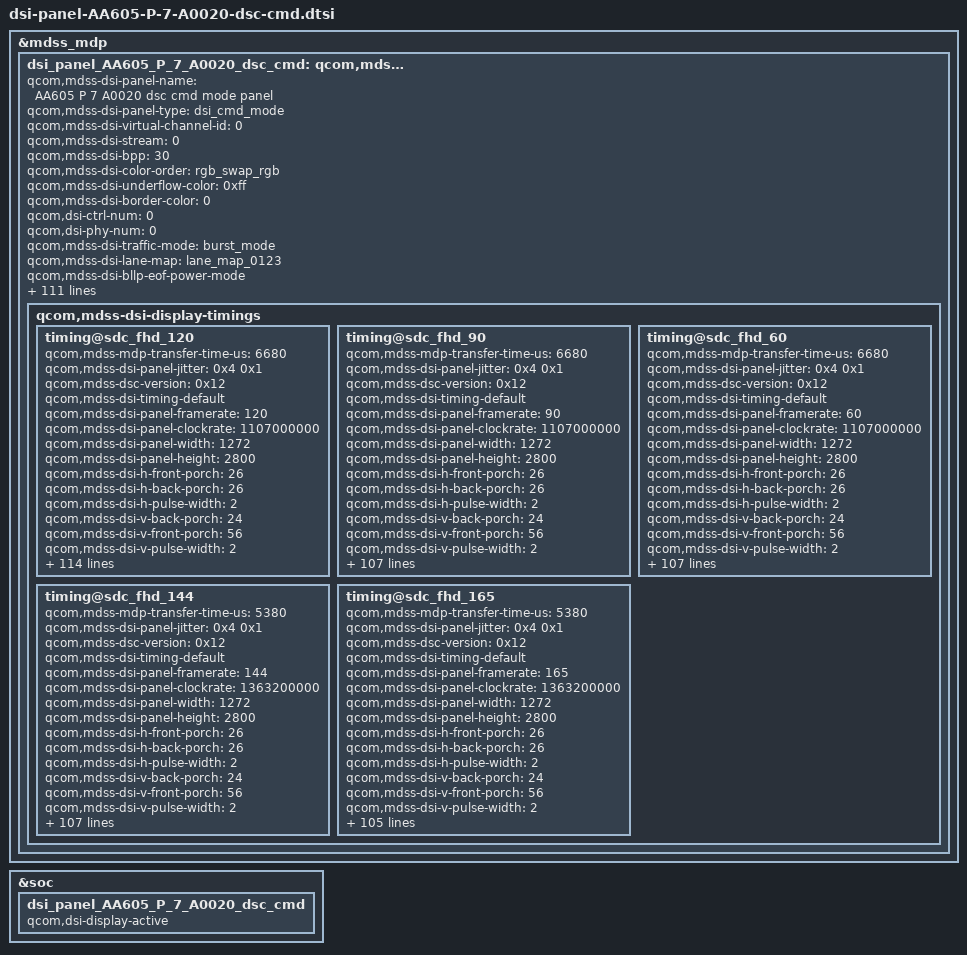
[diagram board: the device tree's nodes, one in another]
&mdss_mdp {
	dsi_panel_AA605_P_7_A0020_dsc_cmd: qcom,mdss_dsi_panel_AA605_P_7_A0020_dsc_cmd {
		qcom,mdss-dsi-panel-name = "AA605 P 7 A0020 dsc cmd mode panel";
		qcom,mdss-dsi-panel-type = "dsi_cmd_mode";
		qcom,mdss-dsi-virtual-channel-id = <0>;
		qcom,mdss-dsi-stream = <0>;
		qcom,mdss-dsi-bpp = <30>;
		qcom,mdss-dsi-color-order = "rgb_swap_rgb";
		qcom,mdss-dsi-underflow-color = <0xff>;
		qcom,mdss-dsi-border-color = <0>;
		qcom,dsi-ctrl-num = <0>;
		qcom,dsi-phy-num = <0>;
		qcom,mdss-dsi-traffic-mode = "burst_mode";
		qcom,mdss-dsi-lane-map = "lane_map_0123";
		qcom,mdss-dsi-bllp-eof-power-mode;
		qcom,mdss-dsi-bllp-power-mode;
		qcom,mdss-dsi-lane-0-state;
		qcom,mdss-dsi-lane-1-state;
		qcom,mdss-dsi-lane-2-state;
		qcom,mdss-dsi-lane-3-state;
		qcom,mdss-dsi-dma-trigger = "trigger_sw";
		qcom,mdss-dsi-dma-schedule-line = <1>;
		qcom,mdss-dsi-dma-schedule-window = <10>;
		qcom,mdss-dsi-mdp-trigger = "none";
		qcom,mdss-dsi-reset-sequence = <1 2>, <0 5>, <1 25>;
		qcom,mdss-dsi-te-pin-select = <1>;
		qcom,mdss-dsi-te-dcs-command = <1>;
		qcom,mdss-pan-physical-width-dimension = <71>;
		qcom,mdss-pan-physical-height-dimension = <157>;
		qcom,mdss-dsi-init-delay-us = <1000>;
		qcom,mdss-dsi-te-check-enable;
		qcom,mdss-dsi-te-using-te-pin;
		//qcom,mdss-dsi-lp11-init;
		qcom,mdss-dsi-wr-mem-start = <0x2c>;
		qcom,mdss-dsi-wr-mem-continue = <0x3c>;
		qcom,mdss-dsi-panel-jitter = <0x4 0x1>;
		qcom,mdss-bl-high2bit;
  		/* HDR Setting */
		qcom,mdss-dsi-panel-hdr-enabled;
		qcom,mdss-dsi-panel-hdr-color-primaries = <15635 16450 34000 16000 13250 34500 7500 3000>;
		//update for [MPC15]android.mediapc.cts.PerformanceClassTest#testDisplayHdr pass
		//qcom,mdss-dsi-panel-peak-brightness = <5400000>;
		qcom,mdss-dsi-panel-peak-brightness = <20000000>;
		qcom,mdss-dsi-panel-average-brightness = <2000000>;
		qcom,mdss-dsi-panel-blackness-level = <4000>;
		qcom,dynamic-mode-switch-enabled;
		qcom,dynamic-mode-switch-type = "dynamic-resolution-switch-immediate";
		qcom,mdss-dsi-display-timings {
			timing@sdc_fhd_120 {
				#include "dsi-panel-AA605-P-7-A0020-common-effect.dtsi"
				#include "dsi-panel-AA605-P-7-A0020-common.dtsi"
				qcom,mdss-mdp-transfer-time-us = <6680>;
				qcom,mdss-dsi-panel-jitter = <0x4 0x1>;
				qcom,mdss-dsc-version = <0x12>;
				qcom,mdss-dsi-timing-default;
				qcom,mdss-dsi-panel-framerate = <120>;
				qcom,mdss-dsi-panel-clockrate = <1107000000>;
				qcom,mdss-dsi-panel-width = <1272>;
				qcom,mdss-dsi-panel-height = <2800>;

				qcom,mdss-dsi-h-front-porch = <26>;
				qcom,mdss-dsi-h-back-porch = <26>;
				qcom,mdss-dsi-h-pulse-width = <2>;
				qcom,mdss-dsi-v-back-porch = <24>;
				qcom,mdss-dsi-v-front-porch = <56>;
				qcom,mdss-dsi-v-pulse-width = <2>;
				qcom,mdss-dsi-h-sync-pulse = <0>;

				oplus,ofp-need-to-sync-data-in-aod-unlocking;
				oplus,ofp-aod-off-insert-black-frame = <1>;
				oplus,ofp-aod-off-black-frame-total-time = <42>;
				oplus,ofp-need-to-separate-backlight;
				oplus,ofp-backlight-on-period = <1>;

				qcom,mdss-dsi-timing-switch-command = [
					39 00 00 40 00 00 04 FF 5A A5 08
					15 00 00 40 00 00 02 98 02
					39 00 00 40 00 00 04 FF 5A A5 4F
					15 00 00 40 00 00 02 80 01
					15 00 00 40 00 00 02 81 06
					15 00 00 40 00 00 02 88 78
					39 00 00 40 00 00 04 FF 5A A5 53
					39 00 00 40 00 00 06 90 44 00 00 04 00
					39 00 00 40 00 00 06 FE 44 00 00 04 00
					39 00 00 40 00 00 06 FE 44 00 00 04 00
					39 00 00 40 00 00 06 FE 44 00 00 04 00
					15 00 00 40 00 00 02 F0 01
					15 00 00 40 00 00 02 00 00
					15 00 00 40 00 00 02 00 00
					15 00 00 40 00 00 02 00 00
					15 00 00 40 00 00 02 00 00
					15 00 00 40 00 00 02 00 00
					15 00 00 40 00 00 02 00 00
					15 00 00 40 00 00 02 00 00
					15 00 00 40 00 00 02 00 00
					39 00 00 40 00 00 04 FF 5A A5 63
					39 00 00 40 00 00 06 F1 20 20 20 20 20
					39 00 00 40 00 00 06 FE 20 20 20 20 20
					39 00 00 40 00 00 06 FE 00 00 00 00 00
					15 00 00 40 00 00 02 FE 00
					15 00 00 40 00 00 02 00 00
					15 00 00 40 00 00 02 00 00
					15 00 00 40 00 00 02 00 00
					15 00 00 40 00 00 02 00 00
					15 00 00 40 00 00 02 00 00
					39 00 00 40 00 00 06 F2 F0 F0 F0 F0 F0
					39 00 00 40 00 00 06 FE F0 F0 F0 F0 F0
					39 00 00 40 00 00 06 FE 00 00 00 00 00
					15 00 00 40 00 00 02 FE 00
					15 00 00 40 00 00 02 00 00
					15 00 00 40 00 00 02 00 00
					15 00 00 40 00 00 02 00 00
					15 00 00 40 00 00 02 00 00
					15 00 00 40 00 00 02 00 00
					39 00 00 40 00 00 06 F3 00 00 00 00 00
					39 00 00 40 00 00 06 FE 00 00 00 00 00
					39 00 00 40 00 00 06 FE 00 00 00 00 00
					15 00 00 40 00 00 02 FE 00
					15 00 00 40 00 00 02 00 00
					15 00 00 40 00 00 02 00 00
					15 00 00 40 00 00 02 00 00
					15 00 00 40 00 00 02 00 00
					15 00 00 40 00 00 02 00 00
					39 00 00 40 00 00 06 F4 00 00 00 00 00
					39 00 00 40 00 00 06 FE 00 00 00 00 00
					39 00 00 40 00 00 06 FE 00 00 00 00 00
					15 00 00 40 00 00 02 FE 00
					15 00 00 40 00 00 02 00 00
					15 00 00 40 00 00 02 00 00
					15 00 00 40 00 00 02 00 00
					15 00 00 40 00 00 02 00 00
					15 00 00 40 00 00 02 00 00
					15 00 00 40 00 00 02 00 00
					15 00 00 40 00 00 02 00 00
					15 00 00 40 00 00 02 00 00
					39 00 00 40 00 00 04 FF 5A A5 53
					15 00 00 40 00 00 02 F0 00
					39 00 00 40 00 00 04 FF 5A A5 00
					39 00 00 40 00 00 04 FF 5A A5 00
					15 00 00 40 00 00 02 60 00
					15 00 00 40 00 00 02 7D 00

					39 00 00 40 00 00 04 FF 5A A5 4F // sync setting
					15 00 00 40 00 00 02 8A 78
					39 00 00 40 00 00 04 FF 5A A5 20 // sync setting
					15 00 00 40 00 00 02 BB 05

					39 00 00 40 00 00 04 FF 5A A5 08
					15 00 00 40 00 00 02 98 A6
					39 00 00 40 00 00 04 FF 5A A5 00
					15 00 00 40 00 00 02 00 00
					39 00 00 40 00 00 04 FF 5A A5 4F
					15 00 00 00 00 00 02 8B 78
				];
				qcom,mdss-dsi-on-command = [
					39 00 00 40 00 00 04 FF 5A A5 08 // 1~2: Sleepoutdon'treload
					15 00 00 40 00 00 02 C8 62
					39 00 00 40 00 00 04 FF 5A A5 21 // 3~4:  Flashreloadenable
					15 00 00 40 00 00 02 A4 38
					39 00 00 40 00 00 04 FF 5A A5 23
					15 00 00 40 00 00 02 85 15
					39 00 00 40 00 00 04 FF 5A A5 06
					15 00 00 40 00 00 02 C6 01
					39 00 00 40 00 00 04 FF 5A A5 08
					15 00 00 40 00 00 02 D2 05
					15 00 00 40 00 00 02 D3 01
					39 00 00 40 00 00 09 ED FC 0C 06 00 E3 F1 09 FF
					39 00 00 00 00 00 09 EE FF FD 82 00 20 03 00 00

					39 00 00 40 00 00 04 FF 5A A5 22
					39 00 00 40 00 00 08 D8 01 03 11 10 3B 18 18 //120&60HZ
					39 00 00 40 00 00 08 D9 01 01 11 10 3B 18 18 //90HZ
					39 00 00 40 00 00 08 DA 00 F8 11 10 2E 17 17 //144HZ
					39 00 00 40 00 00 08 DB 00 F9 11 10 2E 17 17 //165HZ
					39 00 00 40 00 00 0A DC 84 94 BB 00 20 C4 A1 CC 10
					15 00 00 40 00 00 02 DD 01
					15 00 00 40 00 00 02 DE F1
					15 00 00 40 00 00 02 DF 80
					39 00 00 40 00 00 07 E0 02 00 5F 21 00 28

					39 00 00 40 00 00 04 FF 5A A5 02 // sync setting
					39 00 00 40 00 00 03 B0 00 83
					39 00 00 40 00 00 04 FF 5A A5 2D
					15 00 00 40 00 00 02 F6 12
					39 00 00 40 00 00 18 EF 00 00 00 00 00 00 00 00 00 00 00 00 00 00 00 00 00 00 00 00 00 40 0B
					39 00 00 40 00 00 18 F0 00 00 00 00 00 00 00 00 00 00 00 00 00 00 00 00 00 00 00 00 00 40 0B
					39 00 00 40 00 00 04 FF 5A A5 1C // Implementation of measures for addressing abnormal power-on issues of VCI, dvt has already opt
					39 00 00 40 00 00 3A E3 08 00 00 77 01 00 04 14 00 04 14 00 38 10 00 38 10 00 D4 00 00 28 24 00 44 30 00 D4 30 00 47 30 00 F0 00 00 89 00 00 89 00 00 44 00 00 08 00 00 7B 00 00 7B 00 00 24 00 00
					39 00 00 40 00 00 04 FF 5A A5 20 // Correct the reverse configuration of sync settings; dvt has already opt
					15 00 00 40 00 00 02 BA 04 //VSYNC
					15 00 00 00 00 00 02 BB 05 //HSYNC

					39 00 00 40 00 00 04 FF 5A A5 00
					15 00 00 40 00 00 02 7D 00
					15 00 00 40 00 00 02 5E 01
					15 00 00 40 00 00 02 60 00
					15 00 00 40 00 00 02 61 03
					15 00 00 40 00 00 02 6D 01
					15 00 00 40 00 00 02 35 00 // TE on
					15 00 00 40 00 00 02 53 20 // BCOn
					// 120hz
					39 00 00 40 00 00 04 FF 5A A5 53
					39 00 00 40 00 00 06 90 44 00 00 04 00
					39 00 00 40 00 00 06 FE 44 00 00 04 00
					39 00 00 40 00 00 06 FE 44 00 00 04 00
					39 00 00 40 00 00 06 FE 44 00 00 04 00
					15 00 00 40 00 00 02 F0 01
					39 00 00 40 00 00 04 FF 5A A5 63
					39 00 00 40 00 00 06 F1 20 20 20 20 20
					39 00 00 40 00 00 06 FE 20 20 20 20 20
					39 00 00 40 00 00 06 FE 00 00 00 00 00
					15 00 00 40 00 00 02 FE 00
					39 00 00 40 00 00 06 F2 F0 F0 F0 F0 F0
					39 00 00 40 00 00 06 FE F0 F0 F0 F0 F0
					39 00 00 40 00 00 06 FE 00 00 00 00 00
					15 00 00 40 00 00 02 FE 00
					39 00 00 40 00 00 06 F3 00 00 00 00 00
					39 00 00 40 00 00 06 FE 00 00 00 00 00
					39 00 00 40 00 00 06 FE 00 00 00 00 00
					15 00 00 40 00 00 02 FE 00
					39 00 00 40 00 00 06 F4 00 00 00 00 00
					39 00 00 40 00 00 06 FE 00 00 00 00 00
					39 00 00 40 00 00 06 FE 00 00 00 00 00
					15 00 00 40 00 00 02 FE 00
					39 00 00 40 00 00 04 FF 5A A5 53
					15 00 00 40 00 00 02 F0 00
					39 00 00 40 00 00 04 FF 5A A5 00
					39 00 00 40 00 00 04 FF 5A A5 00
					15 00 00 40 00 00 02 60 00
					15 00 00 00 00 00 02 7D 00
					// Evt Output enable for Hsync and Vsync
					39 00 00 40 00 00 04 FF 5A A5 20
					15 00 00 40 00 00 02 BA 04
					15 00 00 00 00 00 02 BB 05
					// ODC ON
					39 00 00 40 00 00 04 FF 5A A5 49
					15 00 00 40 00 00 02 E0 01
					// add demura para
					39 00 00 40 00 00 04 FF 5A A5 53
					15 00 00 40 00 00 02 F0 01
					39 00 00 40 00 00 04 FF 5A A5 63
					39 00 00 40 00 00 11 F1 20 20 20 20 20 20 20 20 20 20 00 00 00 00 00 00
					39 00 00 40 00 00 11 F2 80 80 80 80 80 80 80 80 80 80 00 00 00 00 00 00
					39 00 00 40 00 00 11 F3 00 00 00 00 00 00 00 00 00 00 00 00 00 00 00 00
					39 00 00 40 00 00 11 F4 00 00 00 00 00 00 00 00 00 00 00 00 00 00 00 00
					39 00 00 40 00 00 04 FF 5A A5 53
					15 00 00 00 00 00 02 F0 00

					15 00 00 00 78 00 02 11 00
					15 00 00 00 14 00 02 29 00
				];
				qcom,mdss-dsi-off-command=[
					05 00 00 00 14 00 01 28
					05 00 00 00 78 00 01 10
				];
				qcom,mdss-dsi-timing-switch-compensation-command = [
					39 00 00 40 00 00 04 FF 5A A5 08 // PAGE 08
					15 00 00 40 00 00 02 98 02 //Queue Start Close CDM FIFO Reset
					39 00 00 40 00 00 04 FF 5A A5 4F //CMD_Q
					15 00 00 40 00 00 02 80 01 //Enable MSFC
					15 00 00 40 00 00 02 81 06 //04 Rising,05Falling
					15 00 00 40 00 00 02 88 78 // cmd core0 queue start
					//queue1_str
					39 00 00 40 00 00 04 FF 5A A5 24
					39 00 00 40 00 00 06 C9 00 00 00 10 00
					39 00 00 40 00 00 04 FE 30 00 50
					39 00 00 40 00 00 06 CA 00 70 00 B0 00
					39 00 00 40 00 00 04 FE F0 01 30
					39 00 00 40 00 00 06 CB 01 70 01 C0 02
					39 00 00 40 00 00 04 FE 70 02 F0
					39 00 00 40 00 00 06 CC 03 E0 04 F0 05
					39 00 00 40 00 00 04 FE F0 06 E0
					39 00 00 40 00 00 06 CD 08 F0 0A D0 0B
					39 00 00 40 00 00 04 FE 90 0C C0
					39 00 00 40 00 00 06 CE 0D F0 0E 70 0E
					39 00 00 40 00 00 04 FE F0 0F F0
					39 00 00 40 00 00 04 FF 5A A5 4F // PAGE 4F
					15 00 00 40 00 00 02 8A 78
					//queue2_str
					39 00 00 40 00 00 04 FF 5A A5 00
					15 00 00 40 00 00 02 60 00
					15 00 00 40 00 00 02 7D 00
					39 00 00 40 00 00 04 FF 5A A5 24
					39 00 00 40 00 00 06 C9 00 00 00 10 00
					39 00 00 40 00 00 04 FE 30 00 50
					39 00 00 40 00 00 06 CA 00 70 00 B0 00
					39 00 00 40 00 00 04 FE F0 01 30
					39 00 00 40 00 00 06 CB 01 70 01 F0 02
					39 00 00 40 00 00 04 FE 70 02 F0
					39 00 00 40 00 00 06 CC 03 F0 04 F0 05
					39 00 00 40 00 00 04 FE F0 06 F0
					39 00 00 40 00 00 06 CD 08 F0 0A F0 0B
					39 00 00 40 00 00 04 FE A0 0C F0
					39 00 00 40 00 00 06 CE 0E 10 0E 70 0E
					39 00 00 40 00 00 04 FE F0 0F F0
					//queue2_end
					39 00 00 40 00 00 04 FF 5A A5 53 //Demura Code
					39 00 00 40 00 00 06 90 44 00 00 04 00
					39 00 00 40 00 00 06 FE 44 00 00 04 00
					39 00 00 40 00 00 06 FE 44 00 00 04 00
					39 00 00 40 00 00 06 FE 44 00 00 04 00
					15 00 00 40 00 00 02 F0 01 //MURA_TUNNING
					15 00 00 40 00 00 02 00 00
					15 00 00 40 00 00 02 00 00
					15 00 00 40 00 00 02 00 00
					15 00 00 40 00 00 02 00 00
					15 00 00 40 00 00 02 00 00
					15 00 00 40 00 00 02 00 00
					15 00 00 40 00 00 02 00 00
					15 00 00 40 00 00 02 00 00
					39 00 00 40 00 00 04 FF 5A A5 63
					39 00 00 40 00 00 06 F1 20 20 20 20 20
					39 00 00 40 00 00 06 FE 20 20 20 20 20
					39 00 00 40 00 00 06 FE 00 00 00 00 00
					15 00 00 40 00 00 02 FE 00
					15 00 00 40 00 00 02 00 00
					15 00 00 40 00 00 02 00 00
					15 00 00 40 00 00 02 00 00
					15 00 00 40 00 00 02 00 00
					15 00 00 40 00 00 02 00 00
					39 00 00 40 00 00 06 F2 F0 F0 F0 F0 F0
					39 00 00 40 00 00 06 FE F0 F0 F0 F0 F0
					39 00 00 40 00 00 06 FE 00 00 00 00 00
					15 00 00 40 00 00 02 FE 00
					15 00 00 40 00 00 02 00 00
					15 00 00 40 00 00 02 00 00
					15 00 00 40 00 00 02 00 00
					15 00 00 40 00 00 02 00 00
					15 00 00 40 00 00 02 00 00
					39 00 00 40 00 00 06 F3 00 00 00 00 00
					39 00 00 40 00 00 06 FE 00 00 00 00 00
					39 00 00 40 00 00 06 FE 00 00 00 00 00
					15 00 00 40 00 00 02 FE 00
					15 00 00 40 00 00 02 00 00
					15 00 00 40 00 00 02 00 00
					15 00 00 40 00 00 02 00 00
					15 00 00 40 00 00 02 00 00
					15 00 00 40 00 00 02 00 00
					39 00 00 40 00 00 06 F4 00 00 00 00 00
					39 00 00 40 00 00 06 FE 00 00 00 00 00
					39 00 00 40 00 00 06 FE 00 00 00 00 00
					15 00 00 40 00 00 02 FE 00
					15 00 00 40 00 00 02 00 00
					15 00 00 40 00 00 02 00 00
					15 00 00 40 00 00 02 00 00
					15 00 00 40 00 00 02 00 00
					15 00 00 40 00 00 02 00 00
					15 00 00 40 00 00 02 00 00
					15 00 00 40 00 00 02 00 00
					15 00 00 40 00 00 02 00 00
					39 00 00 40 00 00 04 FF 5A A5 53
					15 00 00 40 00 00 02 F0 00 //
					39 00 00 40 00 00 04 FF 5A A5 4F // sync setting
					15 00 00 40 00 00 02 8A 78
					39 00 00 40 00 00 04 FF 5A A5 20 // sync setting
					15 00 00 40 00 00 02 BB 05
					39 00 00 40 00 00 04 FF 5A A5 00
					39 00 00 40 00 00 04 FF 5A A5 08 //ALL Done open CDM FIFO Reset
					15 00 00 40 00 00 02 98 A6
					39 00 00 40 00 00 04 FF 5A A5 00 //Dummy write
					15 00 00 40 00 00 02 00 00
					39 00 00 40 00 00 04 FF 5A A5 4F // PAGE 4F
					15 00 00 00 00 00 02 8B 78 // cmd core 0 queue all done
					39 00 00 00 00 00 04 FF 5A A5 00
					/* wait for te and blocking one frame */
					39 00 00 20 00 00 04 FF 5A A5 00
				];
				qcom,mdss-dsi-hbm-off-command = [
				];
				qcom,mdss-dsi-hbm-on-command = [
				];
				qcom,mdss-dsi-change-voltage-before-bl-0-command = [
				];
				qcom,mdss-dsi-lhbm-pressed-icon-on-command = [
				];
				qcom,mdss-dsi-lhbm-pressed-icon-off-command = [
				];
				qcom,mdss-dsi-lp1-command = [
					39 00 00 40 00 00 04 FF 5A A5 08
					15 00 00 40 00 00 02 98 02
					39 00 00 40 00 00 04 FF 5A A5 4F
					15 00 00 40 00 00 02 80 01
					15 00 00 40 00 00 02 81 06
					15 00 00 40 00 00 02 88 78
					39 00 00 40 00 00 04 FF 5A A5 02
					39 00 00 40 00 00 03 84 01 1E
					39 00 00 40 00 00 04 FF 5A A5 00
					15 00 00 40 00 00 02 39 00
					39 00 00 40 00 00 04 FF 5A A5 08
					15 00 00 40 00 00 02 98 A6
					39 00 00 40 00 00 04 FF 5A A5 00
					15 00 00 40 00 00 02 00 00
					39 00 00 40 00 00 04 FF 5A A5 4F
					15 00 00 00 00 00 02 8B 78
					39 00 00 00 00 00 05 51 00 00 03 DA
				];
				qcom,mdss-dsi-nolp-command = [
					39 00 00 40 00 00 04 FF 5A A5 08
					15 00 00 40 00 00 02 98 02
					39 00 00 40 00 00 04 FF 5A A5 4F
					15 00 00 40 00 00 02 80 01
					15 00 00 40 00 00 02 81 06
					15 00 00 40 00 00 02 88 78
					39 00 00 40 00 00 04 FF 5A A5 02
					39 00 00 40 00 00 03 84 01 05
					39 00 00 40 00 00 04 FF 5A A5 00
					15 00 00 40 00 00 02 38 00
					39 00 00 40 00 00 04 FF 5A A5 08
					15 00 00 40 00 00 02 98 A6
					39 00 00 40 00 00 04 FF 5A A5 00
					15 00 00 40 00 00 02 00 00
					39 00 00 40 00 00 04 FF 5A A5 4F
					15 00 00 00 00 00 02 8B 78
				];
				qcom,mdss-dsi-aod-off-pwm-mode2-command = [
				];
				qcom,mdss-dsi-aod-off-compensation-command = [
				];
				qcom,mdss-dsi-aod-off-compensation-onepulse-command = [
				];
				qcom,mdss-dsi-aod-high-mode-command = [
					39 00 00 40 00 00 04 FF 5A A5 00
					39 00 00 00 00 00 05 51 00 00 03 DA
				];
				qcom,mdss-dsi-aod-low-mode-command = [
					39 00 00 40 00 00 04 FF 5A A5 00
					39 00 00 00 00 00 05 51 00 00 01 B9
				];
				qcom,mdss-dsi-ultra-low-power-aod-on-command = [
				];
				qcom,mdss-dsi-ultra-low-power-aod-off-command = [
				];
				/* pwm */
				qcom,mdss-dsi-pwm-state-l3tol2-command = [
				];
				qcom,mdss-dsi-pwm-state-l2tol3-command = [
				];
				qcom,mdss-dsi-pwm-switch-mode0-command= [
				];
				qcom,mdss-dsi-pwm-switch-mode2-command = [
				];
				qcom,mdss-dsi-timming-switch-pwm-mode2-command = [
				];
				qcom,mdss-dsi-pwm-switch-mode2-panel-on-command = [
				];
				qcom,mdss-dsi-pwm-state-l1tol3-command = [
				];
				qcom,mdss-dsi-pwm-state-l3tol1-command = [
				];
				qcom,mdss-dsi-hbm-max-command = [
				];
				qcom,mdss-dsi-hbm-exit-max-command = [
				];
				qcom,mdss-dsi-lp1-command-state = "dsi_lp_sync1_mode";
				qcom,mdss-dsi-nolp-command-state = "dsi_lp_sync1_mode";
				qcom,mdss-dsi-aod-off-pwm-mode2-command-state = "dsi_hs_sync1_mode";
				qcom,mdss-dsi-aod-off-compensation-command-state = "dsi_lp_sync1_mode";
				qcom,mdss-dsi-aod-off-compensation-onepulse-command-state = "dsi_lp_sync1_mode";
				qcom,mdss-dsi-nolp-hpwm-command-state = "dsi_lp_sync1_mode";
				qcom,mdss-dsi-hbm-on-command-state = "dsi_hs_sync1_mode";
				qcom,mdss-dsi-hbm-off-command-state = "dsi_hs_sync1_mode";
				qcom,mdss-dsi-panel-read-register-open-state = "dsi_lp_mode";
				qcom,mdss-dsi-panel-read-register-close-state = "dsi_lp_mode";
				qcom,mdss-dsi-lhbm-pressed-icon-gamma-command-state = "dsi_lp_mode";
				qcom,mdss-dsi-lhbm-pressed-icon-grayscale-command-state = "dsi_lp_mode";
				qcom,mdss-dsi-lhbm-pressed-icon-on-command-state = "dsi_lp_mode";
				qcom,mdss-dsi-lhbm-pressed-icon-off-command-state = "dsi_lp_mode";
				qcom,mdss-dsi-lhbm-dbv-alpha-command-state = "dsi_hs_mode";

				qcom,mdss-dsi-reset-scanline-command-state = "dsi_hs_mode";
				qcom,mdss-dsi-recovery-scanline-command-state = "dsi_hs_mode";

				qcom,mdss-dsi-osc-track-on-command-state = "dsi_hs_mode";
				qcom,mdss-dsi-osc-track-off-command-state = "dsi_hs_mode";
				qcom,mdss-dsi-hbm-max-command-state = "dsi_hs_mode";
				qcom,mdss-dsi-hbm-exit-max-command-state = "dsi_hs_mode";

				qcom,lm-split = <636 636>;
				qcom,compression-mode = "dsc";
				qcom,mdss-dsc-encoders = <2>;
				qcom,mdss-dsc-slice-height = <20>;
				qcom,mdss-dsc-slice-width = <636>;
				qcom,mdss-dsc-slice-per-pkt = <2>;
				qcom,mdss-dsc-bit-per-component = <10>;
				qcom,mdss-dsc-bit-per-pixel = <8>;
				qcom,mdss-dsc-block-prediction-enable;
			};
			timing@sdc_fhd_90 {
				#include "dsi-panel-AA605-P-7-A0020-common-effect.dtsi"
				#include "dsi-panel-AA605-P-7-A0020-common.dtsi"
				qcom,mdss-mdp-transfer-time-us = <6680>;
				qcom,mdss-dsi-panel-jitter = <0x4 0x1>;
				qcom,mdss-dsc-version = <0x12>;
				qcom,mdss-dsi-timing-default;
				qcom,mdss-dsi-panel-framerate = <90>;
				qcom,mdss-dsi-panel-clockrate = <1107000000>;
				qcom,mdss-dsi-panel-width = <1272>;
				qcom,mdss-dsi-panel-height = <2800>;

				qcom,mdss-dsi-h-front-porch = <26>;
				qcom,mdss-dsi-h-back-porch = <26>;
				qcom,mdss-dsi-h-pulse-width = <2>;
				qcom,mdss-dsi-v-back-porch = <24>;
				qcom,mdss-dsi-v-front-porch = <56>;
				qcom,mdss-dsi-v-pulse-width = <2>;
				qcom,mdss-dsi-h-sync-pulse = <0>;

				oplus,ofp-need-to-sync-data-in-aod-unlocking;
				oplus,ofp-aod-off-insert-black-frame = <1>;
				oplus,ofp-aod-off-black-frame-total-time = <42>;
				oplus,ofp-need-to-separate-backlight;
				oplus,ofp-backlight-on-period = <1>;

				qcom,mdss-dsi-timing-switch-command = [
					39 00 00 40 00 00 04 FF 5A A5 08
					15 00 00 40 00 00 02 98 02
					39 00 00 40 00 00 04 FF 5A A5 4F
					15 00 00 40 00 00 02 80 01
					15 00 00 40 00 00 02 81 06
					15 00 00 40 00 00 02 88 78
					39 00 00 40 00 00 04 FF 5A A5 53 //Demura Code
					39 00 00 40 00 00 06 90 44 00 00 03 D0
					39 00 00 40 00 00 06 FE 44 00 00 04 00
					39 00 00 40 00 00 06 FE 44 00 00 04 00
					39 00 00 40 00 00 06 FE 44 00 00 04 00
					15 00 00 40 00 00 02 F0 01
					15 00 00 40 00 00 02 00 00
					15 00 00 40 00 00 02 00 00
					15 00 00 40 00 00 02 00 00
					15 00 00 40 00 00 02 00 00
					15 00 00 40 00 00 02 00 00
					15 00 00 40 00 00 02 00 00
					15 00 00 40 00 00 02 00 00
					15 00 00 40 00 00 02 00 00
					39 00 00 40 00 00 04 FF 5A A5 63
					39 00 00 40 00 00 06 F1 20 20 20 20 20
					39 00 00 40 00 00 06 FE 20 20 20 20 20
					39 00 00 40 00 00 06 FE 00 00 00 00 00
					15 00 00 40 00 00 02 FE 00
					15 00 00 40 00 00 02 00 00
					15 00 00 40 00 00 02 00 00
					15 00 00 40 00 00 02 00 00
					15 00 00 40 00 00 02 00 00
					15 00 00 40 00 00 02 00 00
					39 00 00 40 00 00 06 F2 F0 F0 F0 F0 F0
					39 00 00 40 00 00 06 FE F0 F0 F0 F0 F0
					39 00 00 40 00 00 06 FE 00 00 00 00 00
					15 00 00 40 00 00 02 FE 00
					15 00 00 40 00 00 02 00 00
					15 00 00 40 00 00 02 00 00
					15 00 00 40 00 00 02 00 00
					15 00 00 40 00 00 02 00 00
					15 00 00 40 00 00 02 00 00
					39 00 00 40 00 00 06 F3 00 00 00 00 00
					39 00 00 40 00 00 06 FE 00 00 00 00 00
					39 00 00 40 00 00 06 FE 00 00 00 00 00
					15 00 00 40 00 00 02 FE 00
					15 00 00 40 00 00 02 00 00
					15 00 00 40 00 00 02 00 00
					15 00 00 40 00 00 02 00 00
					15 00 00 40 00 00 02 00 00
					15 00 00 40 00 00 02 00 00
					39 00 00 40 00 00 06 F4 00 00 00 00 00
					39 00 00 40 00 00 06 FE 00 00 00 00 00
					39 00 00 40 00 00 06 FE 00 00 00 00 00
					15 00 00 40 00 00 02 FE 00
					15 00 00 40 00 00 02 00 00
					15 00 00 40 00 00 02 00 00
					15 00 00 40 00 00 02 00 00
					15 00 00 40 00 00 02 00 00
					15 00 00 40 00 00 02 00 00
					15 00 00 40 00 00 02 00 00
					15 00 00 40 00 00 02 00 00
					15 00 00 40 00 00 02 00 00
					39 00 00 40 00 00 04 FF 5A A5 53
					15 00 00 40 00 00 02 F0 00
					39 00 00 40 00 00 04 FF 5A A5 00
					39 00 00 40 00 00 04 FF 5A A5 00
					15 00 00 40 00 00 02 60 04
					15 00 00 40 00 00 02 7D 01
					39 00 00 40 00 00 04 FF 5A A5 4F // sync setting
					15 00 00 40 00 00 02 8A 78
					39 00 00 40 00 00 04 FF 5A A5 20 // sync setting
					15 00 00 40 00 00 02 BB 00
					39 00 00 40 00 00 04 FF 5A A5 08
					15 00 00 40 00 00 02 98 A6
					39 00 00 40 00 00 04 FF 5A A5 00
					15 00 00 40 00 00 02 00 00
					39 00 00 40 00 00 04 FF 5A A5 4F
					15 00 00 00 00 00 02 8B 78
				];
				qcom,mdss-dsi-on-command = [
					39 00 00 40 00 00 04 FF 5A A5 08 // 1~2: Sleepoutdon'treload
					15 00 00 40 00 00 02 C8 62
					39 00 00 40 00 00 04 FF 5A A5 21 // 3~4:  Flashreloadenable
					15 00 00 40 00 00 02 A4 38
					39 00 00 40 00 00 04 FF 5A A5 23
					15 00 00 40 00 00 02 85 15
					39 00 00 40 00 00 04 FF 5A A5 06
					15 00 00 40 00 00 02 C6 01
					39 00 00 40 00 00 04 FF 5A A5 08
					15 00 00 40 00 00 02 D2 05
					15 00 00 40 00 00 02 D3 01
					39 00 00 40 00 00 09 ED FC 0C 06 00 E3 F1 09 FF
					39 00 00 00 00 00 09 EE FF FD 82 00 20 03 00 00

					39 00 00 40 00 00 04 FF 5A A5 22
					39 00 00 40 00 00 08 D8 01 03 11 10 3B 18 18 //120&60HZ
					39 00 00 40 00 00 08 D9 01 01 11 10 3B 18 18 //90HZ
					39 00 00 40 00 00 08 DA 00 F8 11 10 2E 17 17 //144HZ
					39 00 00 40 00 00 08 DB 00 F9 11 10 2E 17 17 //165HZ
					39 00 00 40 00 00 0A DC 84 94 BB 00 20 C4 A1 CC 10
					15 00 00 40 00 00 02 DD 01
					15 00 00 40 00 00 02 DE F1
					15 00 00 40 00 00 02 DF 80
					39 00 00 40 00 00 07 E0 02 00 5F 21 00 28

					39 00 00 40 00 00 04 FF 5A A5 02 // sync setting
					39 00 00 40 00 00 03 B0 00 83
					39 00 00 40 00 00 04 FF 5A A5 2D
					15 00 00 40 00 00 02 F6 12
					39 00 00 40 00 00 18 EF 00 00 00 00 00 00 00 00 00 00 00 00 00 00 00 00 00 00 00 00 00 40 0B
					39 00 00 40 00 00 18 F0 00 00 00 00 00 00 00 00 00 00 00 00 00 00 00 00 00 00 00 00 00 40 0B
					39 00 00 40 00 00 04 FF 5A A5 1C // Implementation of measures for addressing abnormal power-on issues of VCI, dvt has already opt
					39 00 00 40 00 00 3A E3 08 00 00 77 01 00 04 14 00 04 14 00 38 10 00 38 10 00 D4 00 00 28 24 00 44 30 00 D4 30 00 47 30 00 F0 00 00 89 00 00 89 00 00 44 00 00 08 00 00 7B 00 00 7B 00 00 24 00 00
					39 00 00 40 00 00 04 FF 5A A5 20 // Correct the reverse configuration of sync settings; dvt has already opt
					15 00 00 40 00 00 02 BA 04 //VSYNC
					15 00 00 00 00 00 02 BB 05 //HSYNC

					39 00 00 40 00 00 04 FF 5A A5 00
					15 00 00 40 00 00 02 7D 00
					15 00 00 40 00 00 02 5E 01
					15 00 00 40 00 00 02 60 00
					15 00 00 40 00 00 02 61 03
					15 00 00 40 00 00 02 6D 01
					15 00 00 40 00 00 02 35 00 // TE on
					15 00 00 40 00 00 02 53 20 // BCOn
					// 90hz
					39 00 00 40 00 00 04 FF 5A A5 53
					39 00 00 40 00 00 06 90 44 00 00 03 D0
					39 00 00 40 00 00 06 FE 44 00 00 04 00
					39 00 00 40 00 00 06 FE 44 00 00 04 00
					39 00 00 40 00 00 06 FE 44 00 00 04 00
					15 00 00 40 00 00 02 F0 01
					39 00 00 40 00 00 04 FF 5A A5 63
					39 00 00 40 00 00 06 F1 20 20 20 20 20
					39 00 00 40 00 00 06 FE 20 20 20 20 20
					39 00 00 40 00 00 06 FE 00 00 00 00 00
					15 00 00 40 00 00 02 FE 00
					39 00 00 40 00 00 06 F2 F0 F0 F0 F0 F0
					39 00 00 40 00 00 06 FE F0 F0 F0 F0 F0
					39 00 00 40 00 00 06 FE 00 00 00 00 00
					15 00 00 40 00 00 02 FE 00
					39 00 00 40 00 00 06 F3 00 00 00 00 00
					39 00 00 40 00 00 06 FE 00 00 00 00 00
					39 00 00 40 00 00 06 FE 00 00 00 00 00
					15 00 00 40 00 00 02 FE 00
					39 00 00 40 00 00 06 F4 00 00 00 00 00
					39 00 00 40 00 00 06 FE 00 00 00 00 00
					39 00 00 40 00 00 06 FE 00 00 00 00 00
					15 00 00 40 00 00 02 FE 00
					39 00 00 40 00 00 04 FF 5A A5 53
					15 00 00 40 00 00 02 F0 00
					39 00 00 40 00 00 04 FF 5A A5 00
					39 00 00 40 00 00 04 FF 5A A5 00
					15 00 00 40 00 00 02 60 04
					15 00 00 00 00 00 02 7D 01
					// Evt Output enable for Hsync and Vsync
					39 00 00 40 00 00 04 FF 5A A5 20
					15 00 00 40 00 00 02 BA 04
					15 00 00 00 00 00 02 BB 05
					// ODC ON
					39 00 00 40 00 00 04 FF 5A A5 49
					15 00 00 40 00 00 02 E0 01
					// add demura para
					39 00 00 40 00 00 04 FF 5A A5 53
					15 00 00 40 00 00 02 F0 01
					39 00 00 40 00 00 04 FF 5A A5 63
					39 00 00 40 00 00 11 F1 20 20 20 20 20 20 20 20 20 20 00 00 00 00 00 00
					39 00 00 40 00 00 11 F2 80 80 80 80 80 80 80 80 80 80 00 00 00 00 00 00
					39 00 00 40 00 00 11 F3 00 00 00 00 00 00 00 00 00 00 00 00 00 00 00 00
					39 00 00 40 00 00 11 F4 00 00 00 00 00 00 00 00 00 00 00 00 00 00 00 00
					39 00 00 40 00 00 04 FF 5A A5 53
					15 00 00 00 00 00 02 F0 00

					15 00 00 00 78 00 02 11 00
					15 00 00 00 14 00 02 29 00
				];
				qcom,mdss-dsi-off-command=[
					05 00 00 00 14 00 01 28
					05 00 00 00 78 00 01 10
				];
				qcom,mdss-dsi-timing-switch-compensation-command = [
					39 00 00 40 00 00 04 FF 5A A5 08 // PAGE 08
					15 00 00 40 00 00 02 98 02 //Queue Start Close CDM FIFO Reset
					39 00 00 40 00 00 04 FF 5A A5 4F //CMD_Q
					15 00 00 40 00 00 02 80 01 //Enable MSFC
					15 00 00 40 00 00 02 81 06 //04 Rising,05Falling
					15 00 00 40 00 00 02 88 78 // cmd core0 queue start
					//queue1_str
					39 00 00 40 00 00 04 FF 5A A5 24
					39 00 00 40 00 00 06 C9 00 00 00 10 00
					39 00 00 40 00 00 04 FE 30 00 50
					39 00 00 40 00 00 06 CA 00 70 00 B0 00
					39 00 00 40 00 00 04 FE F0 01 30
					39 00 00 40 00 00 06 CB 01 70 01 C0 02
					39 00 00 40 00 00 04 FE 70 02 F0
					39 00 00 40 00 00 06 CC 03 E0 04 F0 05
					39 00 00 40 00 00 04 FE F0 06 E0
					39 00 00 40 00 00 06 CD 08 F0 0A D0 0B
					39 00 00 40 00 00 04 FE 90 0C C0
					39 00 00 40 00 00 06 CE 0D F0 0E 70 0E
					39 00 00 40 00 00 04 FE F0 0F F0
					39 00 00 40 00 00 04 FF 5A A5 4F // PAGE 4F
					15 00 00 40 00 00 02 8A 78
					//queue2_str
					39 00 00 40 00 00 04 FF 5A A5 00
					15 00 00 40 00 00 02 60 04
					15 00 00 40 00 00 02 7D 01
					39 00 00 40 00 00 04 FF 5A A5 24
					39 00 00 40 00 00 06 C9 00 00 00 10 00
					39 00 00 40 00 00 04 FE 30 00 50
					39 00 00 40 00 00 06 CA 00 70 00 B0 00
					39 00 00 40 00 00 04 FE F0 01 30
					39 00 00 40 00 00 06 CB 01 70 01 F0 02
					39 00 00 40 00 00 04 FE 70 02 F0
					39 00 00 40 00 00 06 CC 03 F0 04 F0 05
					39 00 00 40 00 00 04 FE F0 06 F0
					39 00 00 40 00 00 06 CD 08 F0 0A F0 0B
					39 00 00 40 00 00 04 FE A0 0C F0
					39 00 00 40 00 00 06 CE 0E 10 0E 70 0E
					39 00 00 40 00 00 04 FE F0 0F F0
					//queue2_end
					39 00 00 40 00 00 04 FF 5A A5 53 //Demura Code
					39 00 00 40 00 00 06 90 44 00 00 03 D0
					39 00 00 40 00 00 06 FE 44 00 00 04 00
					39 00 00 40 00 00 06 FE 44 00 00 04 00
					39 00 00 40 00 00 06 FE 44 00 00 04 00
					15 00 00 40 00 00 02 F0 01 //MURA_TUNNING
					15 00 00 40 00 00 02 00 00
					15 00 00 40 00 00 02 00 00
					15 00 00 40 00 00 02 00 00
					15 00 00 40 00 00 02 00 00
					15 00 00 40 00 00 02 00 00
					15 00 00 40 00 00 02 00 00
					15 00 00 40 00 00 02 00 00
					15 00 00 40 00 00 02 00 00
					39 00 00 40 00 00 04 FF 5A A5 63
					39 00 00 40 00 00 06 F1 20 20 20 20 20
					39 00 00 40 00 00 06 FE 20 20 20 20 20
					39 00 00 40 00 00 06 FE 00 00 00 00 00
					15 00 00 40 00 00 02 FE 00
					15 00 00 40 00 00 02 00 00
					15 00 00 40 00 00 02 00 00
					15 00 00 40 00 00 02 00 00
					15 00 00 40 00 00 02 00 00
					15 00 00 40 00 00 02 00 00
					39 00 00 40 00 00 06 F2 F0 F0 F0 F0 F0
					39 00 00 40 00 00 06 FE F0 F0 F0 F0 F0
					39 00 00 40 00 00 06 FE 00 00 00 00 00
					15 00 00 40 00 00 02 FE 00
					15 00 00 40 00 00 02 00 00
					15 00 00 40 00 00 02 00 00
					15 00 00 40 00 00 02 00 00
					15 00 00 40 00 00 02 00 00
					15 00 00 40 00 00 02 00 00
					39 00 00 40 00 00 06 F3 00 00 00 00 00
					39 00 00 40 00 00 06 FE 00 00 00 00 00
					39 00 00 40 00 00 06 FE 00 00 00 00 00
					15 00 00 40 00 00 02 FE 00
					15 00 00 40 00 00 02 00 00
					15 00 00 40 00 00 02 00 00
					15 00 00 40 00 00 02 00 00
					15 00 00 40 00 00 02 00 00
					15 00 00 40 00 00 02 00 00
					39 00 00 40 00 00 06 F4 00 00 00 00 00
					39 00 00 40 00 00 06 FE 00 00 00 00 00
					39 00 00 40 00 00 06 FE 00 00 00 00 00
					15 00 00 40 00 00 02 FE 00
					15 00 00 40 00 00 02 00 00
					15 00 00 40 00 00 02 00 00
					15 00 00 40 00 00 02 00 00
					15 00 00 40 00 00 02 00 00
					15 00 00 40 00 00 02 00 00
					15 00 00 40 00 00 02 00 00
					15 00 00 40 00 00 02 00 00
					15 00 00 40 00 00 02 00 00
					39 00 00 40 00 00 04 FF 5A A5 53
					15 00 00 40 00 00 02 F0 00 //
					39 00 00 40 00 00 04 FF 5A A5 4F // sync setting
					15 00 00 40 00 00 02 8A 78
					39 00 00 40 00 00 04 FF 5A A5 20 // sync setting
					15 00 00 40 00 00 02 BB 00
					39 00 00 40 00 00 04 FF 5A A5 00
					39 00 00 40 00 00 04 FF 5A A5 08 //ALL Done open CDM FIFO Reset
					15 00 00 40 00 00 02 98 A6
					39 00 00 40 00 00 04 FF 5A A5 00 //Dummy write
					15 00 00 40 00 00 02 00 00
					39 00 00 40 00 00 04 FF 5A A5 4F // PAGE 4F
					15 00 00 00 00 00 02 8B 78 // cmd core 0 queue all done
					39 00 00 00 00 00 04 FF 5A A5 00
					/* wait for te and blocking one frame */
					39 00 00 20 00 00 04 FF 5A A5 00
				];
				qcom,mdss-dsi-hbm-off-command = [
				];
				qcom,mdss-dsi-hbm-on-command = [
				];
				qcom,mdss-dsi-change-voltage-before-bl-0-command = [
				];
				qcom,mdss-dsi-lhbm-pressed-icon-on-command = [
				];
				qcom,mdss-dsi-lhbm-pressed-icon-off-command = [
				];
				qcom,mdss-dsi-lp1-command = [
					39 00 00 40 00 00 04 FF 5A A5 08
					15 00 00 40 00 00 02 98 02
					39 00 00 40 00 00 04 FF 5A A5 4F
					15 00 00 40 00 00 02 80 01
					15 00 00 40 00 00 02 81 06
					15 00 00 40 00 00 02 88 78
					39 00 00 40 00 00 04 FF 5A A5 02
					39 00 00 40 00 00 03 84 01 1E
					39 00 00 40 00 00 04 FF 5A A5 00
					15 00 00 40 00 00 02 39 00
					39 00 00 40 00 00 04 FF 5A A5 08
					15 00 00 40 00 00 02 98 A6
					39 00 00 40 00 00 04 FF 5A A5 00
					15 00 00 40 00 00 02 00 00
					39 00 00 40 00 00 04 FF 5A A5 4F
					15 00 00 00 00 00 02 8B 78
					39 00 00 00 00 00 05 51 00 00 03 DA
				];
				qcom,mdss-dsi-nolp-command = [
					39 00 00 40 00 00 04 FF 5A A5 08
					15 00 00 40 00 00 02 98 02
					39 00 00 40 00 00 04 FF 5A A5 4F
					15 00 00 40 00 00 02 80 01
					15 00 00 40 00 00 02 81 06
					15 00 00 40 00 00 02 88 78
					39 00 00 40 00 00 04 FF 5A A5 02
					39 00 00 40 00 00 03 84 01 05
					39 00 00 40 00 00 04 FF 5A A5 00
					15 00 00 40 00 00 02 38 00
					39 00 00 40 00 00 04 FF 5A A5 08
					15 00 00 40 00 00 02 98 A6
					39 00 00 40 00 00 04 FF 5A A5 00
					15 00 00 40 00 00 02 00 00
					39 00 00 40 00 00 04 FF 5A A5 4F
					15 00 00 00 00 00 02 8B 78
				];
				qcom,mdss-dsi-aod-off-pwm-mode2-command = [
				];
				qcom,mdss-dsi-aod-off-compensation-command = [
				];
				qcom,mdss-dsi-aod-off-compensation-onepulse-command = [
				];
				qcom,mdss-dsi-aod-high-mode-command = [
					39 00 00 40 00 00 04 FF 5A A5 00
					39 00 00 00 00 00 05 51 00 00 03 DA
				];
				qcom,mdss-dsi-aod-low-mode-command = [
					39 00 00 40 00 00 04 FF 5A A5 00
					39 00 00 00 00 00 05 51 00 00 01 B9
				];
				qcom,mdss-dsi-ultra-low-power-aod-on-command = [
				];
				qcom,mdss-dsi-ultra-low-power-aod-off-command = [
				];
				/* pwm */
				qcom,mdss-dsi-pwm-state-l3tol2-command = [
				];
				qcom,mdss-dsi-pwm-state-l2tol3-command = [
				];
				qcom,mdss-dsi-pwm-switch-mode0-command= [
				];
				qcom,mdss-dsi-pwm-switch-mode2-command = [
				];
				qcom,mdss-dsi-timming-switch-pwm-mode2-command = [
				];
				qcom,mdss-dsi-pwm-switch-mode2-panel-on-command = [
				];
				qcom,mdss-dsi-pwm-state-l1tol3-command = [
				];
				qcom,mdss-dsi-pwm-state-l3tol1-command = [
				];
				qcom,mdss-dsi-hbm-max-command = [
				];
				qcom,mdss-dsi-hbm-exit-max-command = [
				];
				qcom,mdss-dsi-lp1-command-state = "dsi_lp_sync1_mode";
				qcom,mdss-dsi-nolp-command-state = "dsi_lp_sync1_mode";
				qcom,mdss-dsi-aod-off-pwm-mode2-command-state = "dsi_hs_sync1_mode";
				qcom,mdss-dsi-aod-off-compensation-command-state = "dsi_lp_sync1_mode";
				qcom,mdss-dsi-aod-off-compensation-onepulse-command-state = "dsi_lp_sync1_mode";
				qcom,mdss-dsi-nolp-hpwm-command-state = "dsi_lp_sync1_mode";
				qcom,mdss-dsi-hbm-on-command-state = "dsi_hs_sync1_mode";
				qcom,mdss-dsi-hbm-off-command-state = "dsi_hs_sync1_mode";
				qcom,mdss-dsi-panel-read-register-open-state = "dsi_lp_mode";
				qcom,mdss-dsi-panel-read-register-close-state = "dsi_lp_mode";
				qcom,mdss-dsi-lhbm-pressed-icon-gamma-command-state = "dsi_lp_mode";
				qcom,mdss-dsi-lhbm-pressed-icon-grayscale-command-state = "dsi_lp_mode";
				qcom,mdss-dsi-lhbm-pressed-icon-on-command-state = "dsi_lp_mode";
				qcom,mdss-dsi-lhbm-pressed-icon-off-command-state = "dsi_lp_mode";
				qcom,mdss-dsi-lhbm-dbv-alpha-command-state = "dsi_hs_mode";

				qcom,mdss-dsi-reset-scanline-command-state = "dsi_hs_mode";
				qcom,mdss-dsi-recovery-scanline-command-state = "dsi_hs_mode";

				qcom,mdss-dsi-osc-track-on-command-state = "dsi_hs_mode";
				qcom,mdss-dsi-osc-track-off-command-state = "dsi_hs_mode";
				qcom,mdss-dsi-hbm-max-command-state = "dsi_hs_mode";
				qcom,mdss-dsi-hbm-exit-max-command-state = "dsi_hs_mode";

				qcom,lm-split = <636 636>;
				qcom,compression-mode = "dsc";
				qcom,mdss-dsc-encoders = <2>;
				qcom,mdss-dsc-slice-height = <20>;
				qcom,mdss-dsc-slice-width = <636>;
				qcom,mdss-dsc-slice-per-pkt = <2>;
				qcom,mdss-dsc-bit-per-component = <10>;
				qcom,mdss-dsc-bit-per-pixel = <8>;
				qcom,mdss-dsc-block-prediction-enable;
			};
			timing@sdc_fhd_60 {
				#include "dsi-panel-AA605-P-7-A0020-common-effect.dtsi"
				#include "dsi-panel-AA605-P-7-A0020-common.dtsi"
				qcom,mdss-mdp-transfer-time-us = <6680>;
				qcom,mdss-dsi-panel-jitter = <0x4 0x1>;
				qcom,mdss-dsc-version = <0x12>;
				qcom,mdss-dsi-timing-default;
				qcom,mdss-dsi-panel-framerate = <60>;
				qcom,mdss-dsi-panel-clockrate = <1107000000>;
				qcom,mdss-dsi-panel-width = <1272>;
				qcom,mdss-dsi-panel-height = <2800>;

				qcom,mdss-dsi-h-front-porch = <26>;
				qcom,mdss-dsi-h-back-porch = <26>;
				qcom,mdss-dsi-h-pulse-width = <2>;
				qcom,mdss-dsi-v-back-porch = <24>;
				qcom,mdss-dsi-v-front-porch = <56>;
				qcom,mdss-dsi-v-pulse-width = <2>;
				qcom,mdss-dsi-h-sync-pulse = <0>;

				oplus,ofp-need-to-sync-data-in-aod-unlocking;
				oplus,ofp-aod-off-insert-black-frame = <1>;
				oplus,ofp-aod-off-black-frame-total-time = <42>;
				oplus,ofp-need-to-separate-backlight;
				oplus,ofp-backlight-on-period = <1>;

				qcom,mdss-dsi-timing-switch-command = [
					39 00 00 40 00 00 04 FF 5A A5 08
					15 00 00 40 00 00 02 98 02
					39 00 00 40 00 00 04 FF 5A A5 4F
					15 00 00 40 00 00 02 80 01
					15 00 00 40 00 00 02 81 06
					15 00 00 40 00 00 02 88 78
					39 00 00 40 00 00 04 FF 5A A5 53 //Demura Code
					39 00 00 40 00 00 06 90 44 00 00 03 10
					39 00 00 40 00 00 06 FE 44 00 00 04 00
					39 00 00 40 00 00 06 FE 44 00 00 04 00
					39 00 00 40 00 00 06 FE 44 00 00 04 00
					15 00 00 40 00 00 02 F0 01
					15 00 00 40 00 00 02 00 00
					15 00 00 40 00 00 02 00 00
					15 00 00 40 00 00 02 00 00
					15 00 00 40 00 00 02 00 00
					15 00 00 40 00 00 02 00 00
					15 00 00 40 00 00 02 00 00
					15 00 00 40 00 00 02 00 00
					15 00 00 40 00 00 02 00 00
					39 00 00 40 00 00 04 FF 5A A5 63
					39 00 00 40 00 00 06 F1 20 20 20 20 20
					39 00 00 40 00 00 06 FE 20 20 20 20 20
					39 00 00 40 00 00 06 FE 00 00 00 00 00
					15 00 00 40 00 00 02 FE 00
					15 00 00 40 00 00 02 00 00
					15 00 00 40 00 00 02 00 00
					15 00 00 40 00 00 02 00 00
					15 00 00 40 00 00 02 00 00
					15 00 00 40 00 00 02 00 00
					39 00 00 40 00 00 06 F2 F0 F0 F0 F0 F0
					39 00 00 40 00 00 06 FE F0 F0 F0 F0 F0
					39 00 00 40 00 00 06 FE 00 00 00 00 00
					15 00 00 40 00 00 02 FE 00
					15 00 00 40 00 00 02 00 00
					15 00 00 40 00 00 02 00 00
					15 00 00 40 00 00 02 00 00
					15 00 00 40 00 00 02 00 00
					15 00 00 40 00 00 02 00 00
					39 00 00 40 00 00 06 F3 00 00 00 00 00
					39 00 00 40 00 00 06 FE 00 00 00 00 00
					39 00 00 40 00 00 06 FE 00 00 00 00 00
					15 00 00 40 00 00 02 FE 00
					15 00 00 40 00 00 02 00 00
					15 00 00 40 00 00 02 00 00
					15 00 00 40 00 00 02 00 00
					15 00 00 40 00 00 02 00 00
					15 00 00 40 00 00 02 00 00
					39 00 00 40 00 00 06 F4 00 00 00 00 00
					39 00 00 40 00 00 06 FE 00 00 00 00 00
					39 00 00 40 00 00 06 FE 00 00 00 00 00
					15 00 00 40 00 00 02 FE 00
					15 00 00 40 00 00 02 00 00
					15 00 00 40 00 00 02 00 00
					15 00 00 40 00 00 02 00 00
					15 00 00 40 00 00 02 00 00
					15 00 00 40 00 00 02 00 00
					15 00 00 40 00 00 02 00 00
					15 00 00 40 00 00 02 00 00
					15 00 00 40 00 00 02 00 00
					39 00 00 40 00 00 04 FF 5A A5 53
					15 00 00 40 00 00 02 F0 00
					39 00 00 40 00 00 04 FF 5A A5 00
					15 00 00 40 00 00 02 60 05
					15 00 00 40 00 00 02 7D 00
					39 00 00 40 00 00 04 FF 5A A5 4F // sync setting
					15 00 00 40 00 00 02 8A 78
					39 00 00 40 00 00 04 FF 5A A5 20 // sync setting
					15 00 00 40 00 00 02 BB 06
					39 00 00 40 00 00 04 FF 5A A5 08
					15 00 00 40 00 00 02 98 A6
					39 00 00 40 00 00 04 FF 5A A5 00
					15 00 00 40 00 00 02 00 00
					39 00 00 40 00 00 04 FF 5A A5 4F
					15 00 00 00 00 00 02 8B 78
				];
				qcom,mdss-dsi-on-command = [
					39 00 00 40 00 00 04 FF 5A A5 08 // 1~2: Sleepoutdon'treload
					15 00 00 40 00 00 02 C8 62
					39 00 00 40 00 00 04 FF 5A A5 21 // 3~4:  Flashreloadenable
					15 00 00 40 00 00 02 A4 38
					39 00 00 40 00 00 04 FF 5A A5 23
					15 00 00 40 00 00 02 85 15
					39 00 00 40 00 00 04 FF 5A A5 06
					15 00 00 40 00 00 02 C6 01
					39 00 00 40 00 00 04 FF 5A A5 08
					15 00 00 40 00 00 02 D2 05
					15 00 00 40 00 00 02 D3 01
					39 00 00 40 00 00 09 ED FC 0C 06 00 E3 F1 09 FF
					39 00 00 00 00 00 09 EE FF FD 82 00 20 03 00 00

					39 00 00 40 00 00 04 FF 5A A5 22
					39 00 00 40 00 00 08 D8 01 03 11 10 3B 18 18 //120&60HZ
					39 00 00 40 00 00 08 D9 01 01 11 10 3B 18 18 //90HZ
					39 00 00 40 00 00 08 DA 00 F8 11 10 2E 17 17 //144HZ
					39 00 00 40 00 00 08 DB 00 F9 11 10 2E 17 17 //165HZ
					39 00 00 40 00 00 0A DC 84 94 BB 00 20 C4 A1 CC 10
					15 00 00 40 00 00 02 DD 01
					15 00 00 40 00 00 02 DE F1
					15 00 00 40 00 00 02 DF 80
					39 00 00 40 00 00 07 E0 02 00 5F 21 00 28

					39 00 00 40 00 00 04 FF 5A A5 02 // sync setting
					39 00 00 40 00 00 03 B0 00 83
					39 00 00 40 00 00 04 FF 5A A5 2D
					15 00 00 40 00 00 02 F6 12
					39 00 00 40 00 00 18 EF 00 00 00 00 00 00 00 00 00 00 00 00 00 00 00 00 00 00 00 00 00 40 0B
					39 00 00 40 00 00 18 F0 00 00 00 00 00 00 00 00 00 00 00 00 00 00 00 00 00 00 00 00 00 40 0B
					39 00 00 40 00 00 04 FF 5A A5 1C // Implementation of measures for addressing abnormal power-on issues of VCI, dvt has already opt
					39 00 00 40 00 00 3A E3 08 00 00 77 01 00 04 14 00 04 14 00 38 10 00 38 10 00 D4 00 00 28 24 00 44 30 00 D4 30 00 47 30 00 F0 00 00 89 00 00 89 00 00 44 00 00 08 00 00 7B 00 00 7B 00 00 24 00 00
					39 00 00 40 00 00 04 FF 5A A5 20 // Correct the reverse configuration of sync settings; dvt has already opt
					15 00 00 40 00 00 02 BA 04 //VSYNC
					15 00 00 00 00 00 02 BB 05 //HSYNC

					39 00 00 40 00 00 04 FF 5A A5 00
					15 00 00 40 00 00 02 7D 00
					15 00 00 40 00 00 02 5E 01
					15 00 00 40 00 00 02 60 00
					15 00 00 40 00 00 02 61 03
					15 00 00 40 00 00 02 6D 01
					15 00 00 40 00 00 02 35 00 // TE on
					15 00 00 40 00 00 02 53 20 // BCOn
					// 60hz
					39 00 00 40 00 00 04 FF 5A A5 53
					39 00 00 40 00 00 06 90 44 00 00 03 10
					39 00 00 40 00 00 06 FE 44 00 00 04 00
					39 00 00 40 00 00 06 FE 44 00 00 04 00
					39 00 00 40 00 00 06 FE 44 00 00 04 00
					15 00 00 40 00 00 02 F0 01
					39 00 00 40 00 00 04 FF 5A A5 63
					39 00 00 40 00 00 06 F1 20 20 20 20 20
					39 00 00 40 00 00 06 FE 20 20 20 20 20
					39 00 00 40 00 00 06 FE 00 00 00 00 00
					15 00 00 40 00 00 02 FE 00
					39 00 00 40 00 00 06 F2 F0 F0 F0 F0 F0
					39 00 00 40 00 00 06 FE F0 F0 F0 F0 F0
					39 00 00 40 00 00 06 FE 00 00 00 00 00
					15 00 00 40 00 00 02 FE 00
					39 00 00 40 00 00 06 F3 00 00 00 00 00
					39 00 00 40 00 00 06 FE 00 00 00 00 00
					39 00 00 40 00 00 06 FE 00 00 00 00 00
					15 00 00 40 00 00 02 FE 00
					39 00 00 40 00 00 06 F4 00 00 00 00 00
					39 00 00 40 00 00 06 FE 00 00 00 00 00
					39 00 00 40 00 00 06 FE 00 00 00 00 00
					15 00 00 40 00 00 02 FE 00
					39 00 00 40 00 00 04 FF 5A A5 53
					15 00 00 40 00 00 02 F0 00
					39 00 00 40 00 00 04 FF 5A A5 00
					15 00 00 40 00 00 02 60 05
					15 00 00 00 00 00 02 7D 00
					// Evt Output enable for Hsync and Vsync
					39 00 00 40 00 00 04 FF 5A A5 20
					15 00 00 40 00 00 02 BA 04
					15 00 00 00 00 00 02 BB 05
					// ODC ON
					39 00 00 40 00 00 04 FF 5A A5 49
					15 00 00 40 00 00 02 E0 01
					// add demura para
					39 00 00 40 00 00 04 FF 5A A5 53
					15 00 00 40 00 00 02 F0 01
					39 00 00 40 00 00 04 FF 5A A5 63
					39 00 00 40 00 00 11 F1 20 20 20 20 20 20 20 20 20 20 00 00 00 00 00 00
					39 00 00 40 00 00 11 F2 80 80 80 80 80 80 80 80 80 80 00 00 00 00 00 00
					39 00 00 40 00 00 11 F3 00 00 00 00 00 00 00 00 00 00 00 00 00 00 00 00
					39 00 00 40 00 00 11 F4 00 00 00 00 00 00 00 00 00 00 00 00 00 00 00 00
					39 00 00 40 00 00 04 FF 5A A5 53
					15 00 00 00 00 00 02 F0 00

					15 00 00 00 78 00 02 11 00
					15 00 00 00 14 00 02 29 00
				];
				qcom,mdss-dsi-off-command=[
					05 00 00 00 14 00 01 28
					05 00 00 00 78 00 01 10
				];
				qcom,mdss-dsi-timing-switch-compensation-command = [
					39 00 00 40 00 00 04 FF 5A A5 08 // PAGE 08
					15 00 00 40 00 00 02 98 02 //Queue Start Close CDM FIFO Reset
					39 00 00 40 00 00 04 FF 5A A5 4F //CMD_Q
					15 00 00 40 00 00 02 80 01 //Enable MSFC
					15 00 00 40 00 00 02 81 06 //04 Rising,05Falling
					15 00 00 40 00 00 02 88 78 // cmd core0 queue start
					//queue1_str
					39 00 00 40 00 00 04 FF 5A A5 24
					39 00 00 40 00 00 06 C9 00 00 00 10 00
					39 00 00 40 00 00 04 FE 30 00 50
					39 00 00 40 00 00 06 CA 00 70 00 B0 00
					39 00 00 40 00 00 04 FE F0 01 30
					39 00 00 40 00 00 06 CB 01 70 01 C0 02
					39 00 00 40 00 00 04 FE 70 02 F0
					39 00 00 40 00 00 06 CC 03 E0 04 F0 05
					39 00 00 40 00 00 04 FE F0 06 E0
					39 00 00 40 00 00 06 CD 08 F0 0A D0 0B
					39 00 00 40 00 00 04 FE 90 0C C0
					39 00 00 40 00 00 06 CE 0D F0 0E 70 0E
					39 00 00 40 00 00 04 FE F0 0F F0
					39 00 00 40 00 00 04 FF 5A A5 4F // PAGE 4F
					15 00 00 40 00 00 02 8A 78
					//queue2_str
					39 00 00 40 00 00 04 FF 5A A5 00
					15 00 00 40 00 00 02 60 05
					15 00 00 40 00 00 02 7D 01
					39 00 00 40 00 00 04 FF 5A A5 24
					39 00 00 40 00 00 06 C9 00 00 00 10 00
					39 00 00 40 00 00 04 FE 30 00 50
					39 00 00 40 00 00 06 CA 00 70 00 B0 00
					39 00 00 40 00 00 04 FE F0 01 30
					39 00 00 40 00 00 06 CB 01 70 01 F0 02
					39 00 00 40 00 00 04 FE 70 02 F0
					39 00 00 40 00 00 06 CC 03 F0 04 F0 05
					39 00 00 40 00 00 04 FE F0 06 F0
					39 00 00 40 00 00 06 CD 08 F0 0A F0 0B
					39 00 00 40 00 00 04 FE A0 0C F0
					39 00 00 40 00 00 06 CE 0E 10 0E 70 0E
					39 00 00 40 00 00 04 FE F0 0F F0
					//queue2_end
					39 00 00 40 00 00 04 FF 5A A5 53 //Demura Code
					39 00 00 40 00 00 06 90 44 00 00 03 10
					39 00 00 40 00 00 06 FE 44 00 00 04 00
					39 00 00 40 00 00 06 FE 44 00 00 04 00
					39 00 00 40 00 00 06 FE 44 00 00 04 00
					15 00 00 40 00 00 02 F0 01 //MURA_TUNNING
					15 00 00 40 00 00 02 00 00
					15 00 00 40 00 00 02 00 00
					15 00 00 40 00 00 02 00 00
					15 00 00 40 00 00 02 00 00
					15 00 00 40 00 00 02 00 00
					15 00 00 40 00 00 02 00 00
					15 00 00 40 00 00 02 00 00
					15 00 00 40 00 00 02 00 00
					39 00 00 40 00 00 04 FF 5A A5 63
					39 00 00 40 00 00 06 F1 20 20 20 20 20
					39 00 00 40 00 00 06 FE 20 20 20 20 20
					39 00 00 40 00 00 06 FE 00 00 00 00 00
					15 00 00 40 00 00 02 FE 00
					15 00 00 40 00 00 02 00 00
					15 00 00 40 00 00 02 00 00
					15 00 00 40 00 00 02 00 00
					15 00 00 40 00 00 02 00 00
					15 00 00 40 00 00 02 00 00
					39 00 00 40 00 00 06 F2 F0 F0 F0 F0 F0
					39 00 00 40 00 00 06 FE F0 F0 F0 F0 F0
					39 00 00 40 00 00 06 FE 00 00 00 00 00
					15 00 00 40 00 00 02 FE 00
					15 00 00 40 00 00 02 00 00
					15 00 00 40 00 00 02 00 00
					15 00 00 40 00 00 02 00 00
					15 00 00 40 00 00 02 00 00
					15 00 00 40 00 00 02 00 00
					39 00 00 40 00 00 06 F3 00 00 00 00 00
					39 00 00 40 00 00 06 FE 00 00 00 00 00
					39 00 00 40 00 00 06 FE 00 00 00 00 00
					15 00 00 40 00 00 02 FE 00
					15 00 00 40 00 00 02 00 00
					15 00 00 40 00 00 02 00 00
					15 00 00 40 00 00 02 00 00
					15 00 00 40 00 00 02 00 00
					15 00 00 40 00 00 02 00 00
					39 00 00 40 00 00 06 F4 00 00 00 00 00
					39 00 00 40 00 00 06 FE 00 00 00 00 00
					39 00 00 40 00 00 06 FE 00 00 00 00 00
					15 00 00 40 00 00 02 FE 00
					15 00 00 40 00 00 02 00 00
					15 00 00 40 00 00 02 00 00
					15 00 00 40 00 00 02 00 00
					15 00 00 40 00 00 02 00 00
					15 00 00 40 00 00 02 00 00
					15 00 00 40 00 00 02 00 00
					15 00 00 40 00 00 02 00 00
					15 00 00 40 00 00 02 00 00
					39 00 00 40 00 00 04 FF 5A A5 53
					15 00 00 40 00 00 02 F0 00 //
					39 00 00 40 00 00 04 FF 5A A5 4F // sync setting
					15 00 00 40 00 00 02 8A 78
					39 00 00 40 00 00 04 FF 5A A5 20 // sync setting
					15 00 00 40 00 00 02 BB 06
					39 00 00 40 00 00 04 FF 5A A5 00
					39 00 00 40 00 00 04 FF 5A A5 08 //ALL Done open CDM FIFO Reset
					15 00 00 40 00 00 02 98 A6
					39 00 00 40 00 00 04 FF 5A A5 00 //Dummy write
					15 00 00 40 00 00 02 00 00
					39 00 00 40 00 00 04 FF 5A A5 4F // PAGE 4F
					15 00 00 00 00 00 02 8B 78 // cmd core 0 queue all done
					39 00 00 00 00 00 04 FF 5A A5 00
					/* wait for te and blocking one frame */
					39 00 00 20 00 00 04 FF 5A A5 00
				];
				qcom,mdss-dsi-hbm-off-command = [
				];
				qcom,mdss-dsi-hbm-on-command = [
				];
				qcom,mdss-dsi-change-voltage-before-bl-0-command = [
				];
				qcom,mdss-dsi-lhbm-pressed-icon-on-command = [
				];
				qcom,mdss-dsi-lhbm-pressed-icon-off-command = [
				];
				qcom,mdss-dsi-lp1-command = [
					39 00 00 40 00 00 04 FF 5A A5 08
					15 00 00 40 00 00 02 98 02
					39 00 00 40 00 00 04 FF 5A A5 4F
					15 00 00 40 00 00 02 80 01
					15 00 00 40 00 00 02 81 06
					15 00 00 40 00 00 02 88 78
					39 00 00 40 00 00 04 FF 5A A5 02
					39 00 00 40 00 00 03 84 01 1E
					39 00 00 40 00 00 04 FF 5A A5 00
					15 00 00 40 00 00 02 39 00
					39 00 00 40 00 00 04 FF 5A A5 08
					15 00 00 40 00 00 02 98 A6
					39 00 00 40 00 00 04 FF 5A A5 00
					15 00 00 40 00 00 02 00 00
					39 00 00 40 00 00 04 FF 5A A5 4F
					15 00 00 00 00 00 02 8B 78
					39 00 00 00 00 00 05 51 00 00 03 DA
				];
				qcom,mdss-dsi-nolp-command = [
					39 00 00 40 00 00 04 FF 5A A5 08
					15 00 00 40 00 00 02 98 02
					39 00 00 40 00 00 04 FF 5A A5 4F
					15 00 00 40 00 00 02 80 01
					15 00 00 40 00 00 02 81 06
					15 00 00 40 00 00 02 88 78
					39 00 00 40 00 00 04 FF 5A A5 02
					39 00 00 40 00 00 03 84 01 05
					39 00 00 40 00 00 04 FF 5A A5 00
					15 00 00 40 00 00 02 38 00
					39 00 00 40 00 00 04 FF 5A A5 08
					15 00 00 40 00 00 02 98 A6
					39 00 00 40 00 00 04 FF 5A A5 00
					15 00 00 40 00 00 02 00 00
					39 00 00 40 00 00 04 FF 5A A5 4F
					15 00 00 00 00 00 02 8B 78
				];
				qcom,mdss-dsi-aod-off-pwm-mode2-command = [
				];
				qcom,mdss-dsi-aod-off-compensation-command = [
				];
				qcom,mdss-dsi-aod-off-compensation-onepulse-command = [
				];
				qcom,mdss-dsi-aod-high-mode-command = [
					39 00 00 40 00 00 04 FF 5A A5 00
					39 00 00 00 00 00 05 51 00 00 03 DA
				];
				qcom,mdss-dsi-aod-low-mode-command = [
					39 00 00 40 00 00 04 FF 5A A5 00
					39 00 00 00 00 00 05 51 00 00 01 B9
				];
				qcom,mdss-dsi-ultra-low-power-aod-on-command = [
				];
				qcom,mdss-dsi-ultra-low-power-aod-off-command = [
				];
				/* pwm */
				qcom,mdss-dsi-pwm-state-l3tol2-command = [
				];
				qcom,mdss-dsi-pwm-state-l2tol3-command = [
				];
				qcom,mdss-dsi-pwm-switch-mode0-command= [
				];
				qcom,mdss-dsi-pwm-switch-mode2-command = [
				];
				qcom,mdss-dsi-timming-switch-pwm-mode2-command = [
				];
				qcom,mdss-dsi-pwm-switch-mode2-panel-on-command = [
				];
				qcom,mdss-dsi-pwm-state-l1tol3-command = [
				];
				qcom,mdss-dsi-pwm-state-l3tol1-command = [
				];
				qcom,mdss-dsi-hbm-max-command = [
				];
				qcom,mdss-dsi-hbm-exit-max-command = [
				];
				qcom,mdss-dsi-lp1-command-state = "dsi_lp_sync1_mode";
				qcom,mdss-dsi-nolp-command-state = "dsi_lp_sync1_mode";
				qcom,mdss-dsi-aod-off-pwm-mode2-command-state = "dsi_hs_sync1_mode";
				qcom,mdss-dsi-aod-off-compensation-command-state = "dsi_lp_sync1_mode";
				qcom,mdss-dsi-aod-off-compensation-onepulse-command-state = "dsi_lp_sync1_mode";
				qcom,mdss-dsi-nolp-hpwm-command-state = "dsi_lp_sync1_mode";
				qcom,mdss-dsi-hbm-on-command-state = "dsi_hs_sync1_mode";
				qcom,mdss-dsi-hbm-off-command-state = "dsi_hs_sync1_mode";
				qcom,mdss-dsi-panel-read-register-open-state = "dsi_lp_mode";
				qcom,mdss-dsi-panel-read-register-close-state = "dsi_lp_mode";
				qcom,mdss-dsi-lhbm-pressed-icon-gamma-command-state = "dsi_lp_mode";
				qcom,mdss-dsi-lhbm-pressed-icon-grayscale-command-state = "dsi_lp_mode";
				qcom,mdss-dsi-lhbm-pressed-icon-on-command-state = "dsi_lp_mode";
				qcom,mdss-dsi-lhbm-pressed-icon-off-command-state = "dsi_lp_mode";
				qcom,mdss-dsi-lhbm-dbv-alpha-command-state = "dsi_hs_mode";

				qcom,mdss-dsi-reset-scanline-command-state = "dsi_hs_mode";
				qcom,mdss-dsi-recovery-scanline-command-state = "dsi_hs_mode";

				qcom,mdss-dsi-osc-track-on-command-state = "dsi_hs_mode";
				qcom,mdss-dsi-osc-track-off-command-state = "dsi_hs_mode";
				qcom,mdss-dsi-hbm-max-command-state = "dsi_hs_mode";
				qcom,mdss-dsi-hbm-exit-max-command-state = "dsi_hs_mode";

				qcom,lm-split = <636 636>;
				qcom,compression-mode = "dsc";
				qcom,mdss-dsc-encoders = <2>;
				qcom,mdss-dsc-slice-height = <20>;
				qcom,mdss-dsc-slice-width = <636>;
				qcom,mdss-dsc-slice-per-pkt = <2>;
				qcom,mdss-dsc-bit-per-component = <10>;
				qcom,mdss-dsc-bit-per-pixel = <8>;
				qcom,mdss-dsc-block-prediction-enable;
			};
			timing@sdc_fhd_144 {
				#include "dsi-panel-AA605-P-7-A0020-common-effect.dtsi"
				#include "dsi-panel-AA605-P-7-A0020-common.dtsi"
				qcom,mdss-mdp-transfer-time-us = <5380>;
				qcom,mdss-dsi-panel-jitter = <0x4 0x1>;
				qcom,mdss-dsc-version = <0x12>;
				qcom,mdss-dsi-timing-default;
				qcom,mdss-dsi-panel-framerate = <144>;
				qcom,mdss-dsi-panel-clockrate = <1363200000>;
				qcom,mdss-dsi-panel-width = <1272>;
				qcom,mdss-dsi-panel-height = <2800>;

				qcom,mdss-dsi-h-front-porch = <26>;
				qcom,mdss-dsi-h-back-porch = <26>;
				qcom,mdss-dsi-h-pulse-width = <2>;
				qcom,mdss-dsi-v-back-porch = <24>;
				qcom,mdss-dsi-v-front-porch = <56>;
				qcom,mdss-dsi-v-pulse-width = <2>;
				qcom,mdss-dsi-h-sync-pulse = <0>;

				oplus,ofp-need-to-sync-data-in-aod-unlocking;
				oplus,ofp-aod-off-insert-black-frame = <1>;
				oplus,ofp-aod-off-black-frame-total-time = <42>;
				oplus,ofp-need-to-separate-backlight;
				oplus,ofp-backlight-on-period = <1>;

				qcom,mdss-dsi-timing-switch-command = [
					39 00 00 40 00 00 04 FF 5A A5 08
					15 00 00 40 00 00 02 98 02
					39 00 00 40 00 00 04 FF 5A A5 4F
					15 00 00 40 00 00 02 80 01
					15 00 00 40 00 00 02 81 06
					15 00 00 40 00 00 02 88 78
					39 00 00 40 00 00 04 FF 5A A5 53 //Demura Code
					39 00 00 40 00 00 06 90 44 00 00 04 00
					39 00 00 40 00 00 06 FE 44 00 00 04 00
					39 00 00 40 00 00 06 FE 44 00 00 04 00
					39 00 00 40 00 00 06 FE 44 00 00 04 00
					15 00 00 40 00 00 02 F0 01
					15 00 00 40 00 00 02 00 00
					15 00 00 40 00 00 02 00 00
					15 00 00 40 00 00 02 00 00
					15 00 00 40 00 00 02 00 00
					15 00 00 40 00 00 02 00 00
					15 00 00 40 00 00 02 00 00
					15 00 00 40 00 00 02 00 00
					15 00 00 40 00 00 02 00 00
					39 00 00 40 00 00 04 FF 5A A5 63
					39 00 00 40 00 00 06 F1 00 00 00 00 00
					39 00 00 40 00 00 06 FE 00 00 00 00 00
					39 00 00 40 00 00 06 FE 00 00 00 00 00
					15 00 00 40 00 00 02 FE 00
					15 00 00 40 00 00 02 00 00
					15 00 00 40 00 00 02 00 00
					15 00 00 40 00 00 02 00 00
					15 00 00 40 00 00 02 00 00
					15 00 00 40 00 00 02 00 00
					39 00 00 40 00 00 06 F2 00 00 00 00 00
					39 00 00 40 00 00 06 FE 00 00 00 00 00
					39 00 00 40 00 00 06 FE 00 00 00 00 00
					15 00 00 40 00 00 02 FE 00
					15 00 00 40 00 00 02 00 00
					15 00 00 40 00 00 02 00 00
					15 00 00 40 00 00 02 00 00
					15 00 00 40 00 00 02 00 00
					15 00 00 40 00 00 02 00 00
					39 00 00 40 00 00 06 F3 00 00 00 00 00
					39 00 00 40 00 00 06 FE 00 20 20 20 20
					39 00 00 40 00 00 06 FE 00 00 00 00 00
					15 00 00 40 00 00 02 FE 00
					15 00 00 40 00 00 02 00 00
					15 00 00 40 00 00 02 00 00
					15 00 00 40 00 00 02 00 00
					15 00 00 40 00 00 02 00 00
					15 00 00 40 00 00 02 00 00
					39 00 00 40 00 00 06 F4 20 20 20 20 20
					39 00 00 40 00 00 06 FE 20 00 00 00 00
					39 00 00 40 00 00 06 FE 00 00 00 00 00
					15 00 00 40 00 00 02 FE 00
					15 00 00 40 00 00 02 00 00
					15 00 00 40 00 00 02 00 00
					15 00 00 40 00 00 02 00 00
					15 00 00 40 00 00 02 00 00
					15 00 00 40 00 00 02 00 00
					15 00 00 40 00 00 02 00 00
					15 00 00 40 00 00 02 00 00
					15 00 00 40 00 00 02 00 00
					39 00 00 40 00 00 04 FF 5A A5 53
					15 00 00 40 00 00 02 F0 00
					39 00 00 40 00 00 04 FF 5A A5 00
					39 00 00 40 00 00 04 FF 5A A5 00
					15 00 00 40 00 00 02 60 01
					15 00 00 40 00 00 02 7D 02
					39 00 00 40 00 00 04 FF 5A A5 4F // sync setting
					15 00 00 40 00 00 02 8A 78
					39 00 00 40 00 00 04 FF 5A A5 20 // sync setting
					15 00 00 40 00 00 02 BB 05
					39 00 00 40 00 00 04 FF 5A A5 08
					15 00 00 40 00 00 02 98 A6
					39 00 00 40 00 00 04 FF 5A A5 00
					15 00 00 40 00 00 02 00 00
					39 00 00 40 00 00 04 FF 5A A5 4F
					15 00 00 00 00 00 02 8B 78
				];
				qcom,mdss-dsi-on-command = [
					39 00 00 40 00 00 04 FF 5A A5 08 // 1~2: Sleepoutdon'treload
					15 00 00 40 00 00 02 C8 62
					39 00 00 40 00 00 04 FF 5A A5 21 // 3~4:  Flashreloadenable
					15 00 00 40 00 00 02 A4 38
					39 00 00 40 00 00 04 FF 5A A5 23
					15 00 00 40 00 00 02 85 15
					39 00 00 40 00 00 04 FF 5A A5 06
					15 00 00 40 00 00 02 C6 01
					39 00 00 40 00 00 04 FF 5A A5 08
					15 00 00 40 00 00 02 D2 05
					15 00 00 40 00 00 02 D3 01
					39 00 00 40 00 00 09 ED FC 0C 06 00 E3 F1 09 FF
					39 00 00 00 00 00 09 EE FF FD 82 00 20 03 00 00

					39 00 00 40 00 00 04 FF 5A A5 22
					39 00 00 40 00 00 08 D8 01 03 11 10 3B 18 18 //120&60HZ
					39 00 00 40 00 00 08 D9 01 01 11 10 3B 18 18 //90HZ
					39 00 00 40 00 00 08 DA 00 F8 11 10 2E 17 17 //144HZ
					39 00 00 40 00 00 08 DB 00 F9 11 10 2E 17 17 //165HZ
					39 00 00 40 00 00 0A DC 84 94 BB 00 20 C4 A1 CC 10
					15 00 00 40 00 00 02 DD 01
					15 00 00 40 00 00 02 DE F1
					15 00 00 40 00 00 02 DF 80
					39 00 00 40 00 00 07 E0 02 00 5F 21 00 28

					39 00 00 40 00 00 04 FF 5A A5 02 // sync setting
					39 00 00 40 00 00 03 B0 00 83
					39 00 00 40 00 00 04 FF 5A A5 2D
					15 00 00 40 00 00 02 F6 12
					39 00 00 40 00 00 18 EF 00 00 00 00 00 00 00 00 00 00 00 00 00 00 00 00 00 00 00 00 00 40 0B
					39 00 00 40 00 00 18 F0 00 00 00 00 00 00 00 00 00 00 00 00 00 00 00 00 00 00 00 00 00 40 0B
					39 00 00 40 00 00 04 FF 5A A5 1C // Implementation of measures for addressing abnormal power-on issues of VCI, dvt has already opt
					39 00 00 40 00 00 3A E3 08 00 00 77 01 00 04 14 00 04 14 00 38 10 00 38 10 00 D4 00 00 28 24 00 44 30 00 D4 30 00 47 30 00 F0 00 00 89 00 00 89 00 00 44 00 00 08 00 00 7B 00 00 7B 00 00 24 00 00
					39 00 00 40 00 00 04 FF 5A A5 20 // Correct the reverse configuration of sync settings; dvt has already opt
					15 00 00 40 00 00 02 BA 04 //VSYNC
					15 00 00 00 00 00 02 BB 05 //HSYNC

					39 00 00 40 00 00 04 FF 5A A5 00
					15 00 00 40 00 00 02 7D 00
					15 00 00 40 00 00 02 5E 01
					15 00 00 40 00 00 02 60 00
					15 00 00 40 00 00 02 61 03
					15 00 00 40 00 00 02 6D 01
					15 00 00 40 00 00 02 35 00 // TE on
					15 00 00 40 00 00 02 53 20 // BCOn
					// 144hz
					39 00 00 40 00 00 04 FF 5A A5 53
					39 00 00 40 00 00 06 90 44 00 00 04 00
					39 00 00 40 00 00 06 FE 44 00 00 04 00
					39 00 00 40 00 00 06 FE 44 00 00 04 00
					39 00 00 40 00 00 06 FE 44 00 00 04 00
					15 00 00 40 00 00 02 F0 01
					39 00 00 40 00 00 04 FF 5A A5 63
					39 00 00 40 00 00 06 F1 00 00 00 00 00
					39 00 00 40 00 00 06 FE 00 00 00 00 00
					39 00 00 40 00 00 06 FE 00 00 00 00 00
					15 00 00 40 00 00 02 FE 00
					39 00 00 40 00 00 06 F2 00 00 00 00 00
					39 00 00 40 00 00 06 FE 00 00 00 00 00
					39 00 00 40 00 00 06 FE 00 00 00 00 00
					15 00 00 40 00 00 02 FE 00
					39 00 00 40 00 00 06 F3 00 00 00 00 00
					39 00 00 40 00 00 06 FE 00 20 20 20 20
					39 00 00 40 00 00 06 FE 00 00 00 00 00
					15 00 00 40 00 00 02 FE 00
					39 00 00 40 00 00 06 F4 20 20 20 20 20
					39 00 00 40 00 00 06 FE 20 00 00 00 00
					39 00 00 40 00 00 06 FE 00 00 00 00 00
					15 00 00 40 00 00 02 FE 00
					39 00 00 40 00 00 04 FF 5A A5 53
					15 00 00 40 00 00 02 F0 00
					39 00 00 40 00 00 04 FF 5A A5 00
					39 00 00 40 00 00 04 FF 5A A5 00
					15 00 00 40 00 00 02 60 01
					15 00 00 00 00 00 02 7D 02
					// Evt Output enable for Hsync and Vsync
					39 00 00 40 00 00 04 FF 5A A5 20
					15 00 00 40 00 00 02 BA 04
					15 00 00 00 00 00 02 BB 05
					// ODC ON
					39 00 00 40 00 00 04 FF 5A A5 49
					15 00 00 40 00 00 02 E0 01
					// add demura para
					39 00 00 40 00 00 04 FF 5A A5 53
					15 00 00 40 00 00 02 F0 01
					39 00 00 40 00 00 04 FF 5A A5 63
					39 00 00 40 00 00 11 F1 20 20 20 20 20 20 20 20 20 20 00 00 00 00 00 00
					39 00 00 40 00 00 11 F2 80 80 80 80 80 80 80 80 80 80 00 00 00 00 00 00
					39 00 00 40 00 00 11 F3 00 00 00 00 00 00 00 00 00 00 00 00 00 00 00 00
					39 00 00 40 00 00 11 F4 00 00 00 00 00 00 00 00 00 00 00 00 00 00 00 00
					39 00 00 40 00 00 04 FF 5A A5 53
					15 00 00 00 00 00 02 F0 00

					15 00 00 00 78 00 02 11 00
					15 00 00 00 14 00 02 29 00
				];
				qcom,mdss-dsi-off-command=[
					05 00 00 00 14 00 01 28
					05 00 00 00 78 00 01 10
				];
				qcom,mdss-dsi-timing-switch-compensation-command = [
					39 00 00 40 00 00 04 FF 5A A5 08 // PAGE 08
					15 00 00 40 00 00 02 98 02 //Queue Start Close CDM FIFO Reset
					39 00 00 40 00 00 04 FF 5A A5 4F //CMD_Q
					15 00 00 40 00 00 02 80 01 //Enable MSFC
					15 00 00 40 00 00 02 81 06 //04 Rising,05Falling
					15 00 00 40 00 00 02 88 78 // cmd core0 queue start
					//queue1_str
					39 00 00 40 00 00 04 FF 5A A5 24
					39 00 00 40 00 00 06 C9 00 00 00 10 00
					39 00 00 40 00 00 04 FE 30 00 50
					39 00 00 40 00 00 06 CA 00 70 00 B0 00
					39 00 00 40 00 00 04 FE F0 01 30
					39 00 00 40 00 00 06 CB 01 70 01 C0 02
					39 00 00 40 00 00 04 FE 70 02 F0
					39 00 00 40 00 00 06 CC 03 E0 04 F0 05
					39 00 00 40 00 00 04 FE F0 06 E0
					39 00 00 40 00 00 06 CD 08 F0 0A D0 0B
					39 00 00 40 00 00 04 FE 90 0C C0
					39 00 00 40 00 00 06 CE 0D F0 0E 70 0E
					39 00 00 40 00 00 04 FE F0 0F F0
					39 00 00 40 00 00 04 FF 5A A5 4F // PAGE 4F
					15 00 00 40 00 00 02 8A 78
					//queue2_str
					39 00 00 40 00 00 04 FF 5A A5 00
					15 00 00 40 00 00 02 60 01
					15 00 00 40 00 00 02 7D 02
					39 00 00 40 00 00 04 FF 5A A5 24
					39 00 00 40 00 00 06 C9 00 00 00 10 00
					39 00 00 40 00 00 04 FE 30 00 50
					39 00 00 40 00 00 06 CA 00 70 00 B0 00
					39 00 00 40 00 00 04 FE F0 01 30
					39 00 00 40 00 00 06 CB 01 70 01 F0 02
					39 00 00 40 00 00 04 FE 70 02 F0
					39 00 00 40 00 00 06 CC 03 F0 04 F0 05
					39 00 00 40 00 00 04 FE F0 06 F0
					39 00 00 40 00 00 06 CD 08 F0 0A F0 0B
					39 00 00 40 00 00 04 FE A0 0C F0
					39 00 00 40 00 00 06 CE 0E 10 0E 70 0E
					39 00 00 40 00 00 04 FE F0 0F F0
					//queue2_end
					39 00 00 40 00 00 04 FF 5A A5 53 //Demura Code
					39 00 00 40 00 00 06 90 44 00 00 03 10
					39 00 00 40 00 00 06 FE 44 00 00 04 00
					39 00 00 40 00 00 06 FE 44 00 00 04 00
					39 00 00 40 00 00 06 FE 44 00 00 04 00
					15 00 00 40 00 00 02 F0 01 //MURA_TUNNING
					15 00 00 40 00 00 02 00 00
					15 00 00 40 00 00 02 00 00
					15 00 00 40 00 00 02 00 00
					15 00 00 40 00 00 02 00 00
					15 00 00 40 00 00 02 00 00
					15 00 00 40 00 00 02 00 00
					15 00 00 40 00 00 02 00 00
					15 00 00 40 00 00 02 00 00
					39 00 00 40 00 00 04 FF 5A A5 63
					39 00 00 40 00 00 06 F1 00 00 00 00 00
					39 00 00 40 00 00 06 FE 00 00 00 00 00
					39 00 00 40 00 00 06 FE 00 00 00 00 00
					15 00 00 40 00 00 02 FE 00
					15 00 00 40 00 00 02 00 00
					15 00 00 40 00 00 02 00 00
					15 00 00 40 00 00 02 00 00
					15 00 00 40 00 00 02 00 00
					15 00 00 40 00 00 02 00 00
					39 00 00 40 00 00 06 F2 00 00 00 00 00
					39 00 00 40 00 00 06 FE 00 00 00 00 00
					39 00 00 40 00 00 06 FE 00 00 00 00 00
					15 00 00 40 00 00 02 FE 00
					15 00 00 40 00 00 02 00 00
					15 00 00 40 00 00 02 00 00
					15 00 00 40 00 00 02 00 00
					15 00 00 40 00 00 02 00 00
					15 00 00 40 00 00 02 00 00
					39 00 00 40 00 00 06 F3 00 00 00 00 00
					39 00 00 40 00 00 06 FE 00 20 20 20 20
					39 00 00 40 00 00 06 FE 00 00 00 00 00
					15 00 00 40 00 00 02 FE 00
					15 00 00 40 00 00 02 00 00
					15 00 00 40 00 00 02 00 00
					15 00 00 40 00 00 02 00 00
					15 00 00 40 00 00 02 00 00
					15 00 00 40 00 00 02 00 00
					39 00 00 40 00 00 06 F4 20 20 20 20 20
					39 00 00 40 00 00 06 FE 20 00 00 00 00
					39 00 00 40 00 00 06 FE 00 00 00 00 00
					15 00 00 40 00 00 02 FE 00
					15 00 00 40 00 00 02 00 00
					15 00 00 40 00 00 02 00 00
					15 00 00 40 00 00 02 00 00
					15 00 00 40 00 00 02 00 00
					15 00 00 40 00 00 02 00 00
					15 00 00 40 00 00 02 00 00
					15 00 00 40 00 00 02 00 00
					15 00 00 40 00 00 02 00 00
					39 00 00 40 00 00 04 FF 5A A5 53
					15 00 00 40 00 00 02 F0 00 //
					39 00 00 40 00 00 04 FF 5A A5 4F // sync setting
					15 00 00 40 00 00 02 8A 78
					39 00 00 40 00 00 04 FF 5A A5 20 // sync setting
					15 00 00 40 00 00 02 BB 06
					39 00 00 40 00 00 04 FF 5A A5 00
					39 00 00 40 00 00 04 FF 5A A5 08 //ALL Done open CDM FIFO Reset
					15 00 00 40 00 00 02 98 A6
					39 00 00 40 00 00 04 FF 5A A5 00 //Dummy write
					15 00 00 40 00 00 02 00 00
					39 00 00 40 00 00 04 FF 5A A5 4F // PAGE 4F
					15 00 00 00 00 00 02 8B 78 // cmd core 0 queue all done
					39 00 00 00 00 00 04 FF 5A A5 00
					/* wait for te and blocking one frame */
					39 00 00 20 00 00 04 FF 5A A5 00
				];
				qcom,mdss-dsi-hbm-off-command = [
				];
				qcom,mdss-dsi-hbm-on-command = [
				];
				qcom,mdss-dsi-change-voltage-before-bl-0-command = [
				];
				qcom,mdss-dsi-lhbm-pressed-icon-on-command = [
				];
				qcom,mdss-dsi-lhbm-pressed-icon-off-command = [
				];
				qcom,mdss-dsi-lp1-command = [
					39 00 00 40 00 00 04 FF 5A A5 08
					15 00 00 40 00 00 02 98 02
					39 00 00 40 00 00 04 FF 5A A5 4F
					15 00 00 40 00 00 02 80 01
					15 00 00 40 00 00 02 81 06
					15 00 00 40 00 00 02 88 78
					39 00 00 40 00 00 04 FF 5A A5 02
					39 00 00 40 00 00 03 84 01 1E
					39 00 00 40 00 00 04 FF 5A A5 00
					15 00 00 40 00 00 02 39 00
					39 00 00 40 00 00 04 FF 5A A5 08
					15 00 00 40 00 00 02 98 A6
					39 00 00 40 00 00 04 FF 5A A5 00
					15 00 00 40 00 00 02 00 00
					39 00 00 40 00 00 04 FF 5A A5 4F
					15 00 00 00 00 00 02 8B 78
					39 00 00 00 00 00 05 51 00 00 03 DA
				];
				qcom,mdss-dsi-nolp-command = [
					39 00 00 40 00 00 04 FF 5A A5 08
					15 00 00 40 00 00 02 98 02
					39 00 00 40 00 00 04 FF 5A A5 4F
					15 00 00 40 00 00 02 80 01
					15 00 00 40 00 00 02 81 06
					15 00 00 40 00 00 02 88 78
					39 00 00 40 00 00 04 FF 5A A5 02
					39 00 00 40 00 00 03 84 01 05
					39 00 00 40 00 00 04 FF 5A A5 00
					15 00 00 40 00 00 02 38 00
					39 00 00 40 00 00 04 FF 5A A5 08
					15 00 00 40 00 00 02 98 A6
					39 00 00 40 00 00 04 FF 5A A5 00
					15 00 00 40 00 00 02 00 00
					39 00 00 40 00 00 04 FF 5A A5 4F
					15 00 00 00 00 00 02 8B 78
				];
				qcom,mdss-dsi-aod-off-pwm-mode2-command = [
				];
				qcom,mdss-dsi-aod-off-compensation-command = [
				];
				qcom,mdss-dsi-aod-off-compensation-onepulse-command = [
				];
				qcom,mdss-dsi-aod-high-mode-command = [
					39 00 00 40 00 00 04 FF 5A A5 00
					39 00 00 00 00 00 05 51 00 00 03 DA
				];
				qcom,mdss-dsi-aod-low-mode-command = [
					39 00 00 40 00 00 04 FF 5A A5 00
					39 00 00 00 00 00 05 51 00 00 01 B9
				];
				qcom,mdss-dsi-ultra-low-power-aod-on-command = [
				];
				qcom,mdss-dsi-ultra-low-power-aod-off-command = [
				];
				/* pwm */
				qcom,mdss-dsi-pwm-state-l3tol2-command = [
				];
				qcom,mdss-dsi-pwm-state-l2tol3-command = [
				];
				qcom,mdss-dsi-pwm-switch-mode0-command= [
				];
				qcom,mdss-dsi-pwm-switch-mode2-command = [
				];
				qcom,mdss-dsi-timming-switch-pwm-mode2-command = [
				];
				qcom,mdss-dsi-pwm-switch-mode2-panel-on-command = [
				];
				qcom,mdss-dsi-pwm-state-l1tol3-command = [
				];
				qcom,mdss-dsi-pwm-state-l3tol1-command = [
				];
				qcom,mdss-dsi-hbm-max-command = [
				];
				qcom,mdss-dsi-hbm-exit-max-command = [
				];
				qcom,mdss-dsi-lp1-command-state = "dsi_lp_sync1_mode";
				qcom,mdss-dsi-nolp-command-state = "dsi_lp_sync1_mode";
				qcom,mdss-dsi-aod-off-pwm-mode2-command-state = "dsi_hs_sync1_mode";
				qcom,mdss-dsi-aod-off-compensation-command-state = "dsi_lp_sync1_mode";
				qcom,mdss-dsi-aod-off-compensation-onepulse-command-state = "dsi_lp_sync1_mode";
				qcom,mdss-dsi-nolp-hpwm-command-state = "dsi_lp_sync1_mode";
				qcom,mdss-dsi-hbm-on-command-state = "dsi_hs_sync1_mode";
				qcom,mdss-dsi-hbm-off-command-state = "dsi_hs_sync1_mode";
				qcom,mdss-dsi-panel-read-register-open-state = "dsi_lp_mode";
				qcom,mdss-dsi-panel-read-register-close-state = "dsi_lp_mode";
				qcom,mdss-dsi-lhbm-pressed-icon-gamma-command-state = "dsi_lp_mode";
				qcom,mdss-dsi-lhbm-pressed-icon-grayscale-command-state = "dsi_lp_mode";
				qcom,mdss-dsi-lhbm-pressed-icon-on-command-state = "dsi_lp_mode";
				qcom,mdss-dsi-lhbm-pressed-icon-off-command-state = "dsi_lp_mode";
				qcom,mdss-dsi-lhbm-dbv-alpha-command-state = "dsi_hs_mode";

				qcom,mdss-dsi-reset-scanline-command-state = "dsi_hs_mode";
				qcom,mdss-dsi-recovery-scanline-command-state = "dsi_hs_mode";

				qcom,mdss-dsi-osc-track-on-command-state = "dsi_hs_mode";
				qcom,mdss-dsi-osc-track-off-command-state = "dsi_hs_mode";
				qcom,mdss-dsi-hbm-max-command-state = "dsi_hs_mode";
				qcom,mdss-dsi-hbm-exit-max-command-state = "dsi_hs_mode";

				qcom,lm-split = <636 636>;
				qcom,compression-mode = "dsc";
				qcom,mdss-dsc-encoders = <2>;
				qcom,mdss-dsc-slice-height = <20>;
				qcom,mdss-dsc-slice-width = <636>;
				qcom,mdss-dsc-slice-per-pkt = <2>;
				qcom,mdss-dsc-bit-per-component = <10>;
				qcom,mdss-dsc-bit-per-pixel = <8>;
				qcom,mdss-dsc-block-prediction-enable;
			};
			timing@sdc_fhd_165 {
				#include "dsi-panel-AA605-P-7-A0020-common-effect.dtsi"
				#include "dsi-panel-AA605-P-7-A0020-common.dtsi"
				qcom,mdss-mdp-transfer-time-us = <5380>;
				qcom,mdss-dsi-panel-jitter = <0x4 0x1>;
				qcom,mdss-dsc-version = <0x12>;
				qcom,mdss-dsi-timing-default;
				qcom,mdss-dsi-panel-framerate = <165>;
				qcom,mdss-dsi-panel-clockrate = <1363200000>;
				qcom,mdss-dsi-panel-width = <1272>;
				qcom,mdss-dsi-panel-height = <2800>;

				qcom,mdss-dsi-h-front-porch = <26>;
				qcom,mdss-dsi-h-back-porch = <26>;
				qcom,mdss-dsi-h-pulse-width = <2>;
				qcom,mdss-dsi-v-back-porch = <24>;
				qcom,mdss-dsi-v-front-porch = <56>;
				qcom,mdss-dsi-v-pulse-width = <2>;
				qcom,mdss-dsi-h-sync-pulse = <0>;

				oplus,ofp-need-to-sync-data-in-aod-unlocking;
				oplus,ofp-aod-off-insert-black-frame = <1>;
				oplus,ofp-aod-off-black-frame-total-time = <42>;
				oplus,ofp-need-to-separate-backlight;
				oplus,ofp-backlight-on-period = <1>;

				qcom,mdss-dsi-timing-switch-command = [
					39 00 00 40 00 00 04 FF 5A A5 08 // PAGE 08
					15 00 00 40 00 00 02 98 02 //Queue Start Close CDM FIFO Reset
					39 00 00 40 00 00 04 FF 5A A5 4F // PAGE 4F
					15 00 00 40 00 00 02 80 01 //Enable MSFC
					15 00 00 40 00 00 02 81 06 //04 Rising,05Falling
					15 00 00 40 00 00 02 88 78 // cmd core0 queue start
					//queue1_str
					39 00 00 40 00 00 04 FF 5A A5 24 // Flashing Code on First Frame
					39 00 00 40 00 00 06 C9 00 00 00 10 00
					39 00 00 40 00 00 04 FE 30 00 50
					39 00 00 40 00 00 06 CA 00 70 00 B0 00
					39 00 00 40 00 00 04 FE F0 01 30 //15
					39 00 00 40 00 00 06 CB 01 70 02 20 02 //23  31
					39 00 00 40 00 00 04 FE 70 02 F0 //39  47
					39 00 00 40 00 00 06 CC 04 00 04 F0 05 //63  79 95
					39 00 00 40 00 00 04 FE F0 07 00 //111
					39 00 00 40 00 00 06 CD 08 F0 0B 10 0B //143 175 186
					39 00 00 40 00 00 04 FE D0 0D 30
					39 00 00 40 00 00 06 CE 0E 20 0E 70 0E //225 231
					39 00 00 40 00 00 04 FE F0 0F F0
					//queue1_end
					39 00 00 40 00 00 04 FF 5A A5 4F // PAGE 4F
					15 00 00 40 00 00 02 8A 78
					//queue2_str
					39 00 00 40 00 00 04 FF 5A A5 00 // Frequency Switching Code
					15 00 00 40 00 00 02 60 02
					15 00 00 40 00 00 02 7D 03
					39 00 00 40 00 00 04 FF 5A A5 24 //Flashing Code on First Frame
					39 00 00 40 00 00 06 C9 00 00 00 10 00
					39 00 00 40 00 00 04 FE 30 00 50
					39 00 00 40 00 00 06 CA 00 70 00 B0 00
					39 00 00 40 00 00 04 FE F0 01 30
					39 00 00 40 00 00 06 CB 01 70 01 F0 02
					39 00 00 40 00 00 04 FE 70 02 F0
					39 00 00 40 00 00 06 CC 03 F0 04 F0 05
					39 00 00 40 00 00 04 FE F0 06 F0
					39 00 00 40 00 00 06 CD 08 F0 0A F0 0B
					39 00 00 40 00 00 04 FE A0 0C F0
					39 00 00 40 00 00 06 CE 0E 10 0E 70 0E
					39 00 00 40 00 00 04 FE F0 0F F0
					39 00 00 40 00 00 04 FF 5A A5 53 //Demura Code
					39 00 00 40 00 00 06 90 44 00 00 04 00
					39 00 00 40 00 00 06 FE 44 00 00 04 00
					39 00 00 40 00 00 06 FE 44 00 00 04 00
					39 00 00 40 00 00 06 FE 44 00 00 04 00
					15 00 00 40 00 00 02 F0 01 //MURA_TUNNING
					15 00 00 40 00 00 02 00 00
					15 00 00 40 00 00 02 00 00
					15 00 00 40 00 00 02 00 00
					15 00 00 40 00 00 02 00 00
					15 00 00 40 00 00 02 00 00
					15 00 00 40 00 00 02 00 00
					15 00 00 40 00 00 02 00 00
					15 00 00 40 00 00 02 00 00
					39 00 00 40 00 00 04 FF 5A A5 63
					39 00 00 40 00 00 06 F1 00 00 00 00 00
					39 00 00 40 00 00 06 FE 00 00 00 00 00
					39 00 00 40 00 00 06 FE 00 00 00 00 00
					15 00 00 40 00 00 02 FE 00
					15 00 00 40 00 00 02 00 00
					15 00 00 40 00 00 02 00 00
					15 00 00 40 00 00 02 00 00
					15 00 00 40 00 00 02 00 00
					15 00 00 40 00 00 02 00 00
					39 00 00 40 00 00 06 F2 00 00 00 00 00
					39 00 00 40 00 00 06 FE 00 00 00 00 00
					39 00 00 40 00 00 06 FE 00 00 00 00 00
					15 00 00 40 00 00 02 FE 00
					15 00 00 40 00 00 02 00 00
					15 00 00 40 00 00 02 00 00
					15 00 00 40 00 00 02 00 00
					15 00 00 40 00 00 02 00 00
					15 00 00 40 00 00 02 00 00
					39 00 00 40 00 00 06 F3 00 00 00 00 00
					39 00 00 40 00 00 06 FE 00 20 20 20 20
					39 00 00 40 00 00 06 FE 00 00 00 00 00
					15 00 00 40 00 00 02 FE 00
					15 00 00 40 00 00 02 00 00
					15 00 00 40 00 00 02 00 00
					15 00 00 40 00 00 02 00 00
					15 00 00 40 00 00 02 00 00
					15 00 00 40 00 00 02 00 00
					39 00 00 40 00 00 06 F4 20 20 20 20 20
					39 00 00 40 00 00 06 FE 20 00 00 00 00
					39 00 00 40 00 00 06 FE 00 00 00 00 00
					15 00 00 40 00 00 02 FE 00
					15 00 00 40 00 00 02 00 00
					15 00 00 40 00 00 02 00 00
					15 00 00 40 00 00 02 00 00
					15 00 00 40 00 00 02 00 00
					15 00 00 40 00 00 02 00 00
					15 00 00 40 00 00 02 00 00
					15 00 00 40 00 00 02 00 00
					15 00 00 40 00 00 02 00 00
					39 00 00 40 00 00 04 FF 5A A5 53
					15 00 00 40 00 00 02 F0 00
					39 00 00 40 00 00 04 FF 5A A5 4F // sync setting
					15 00 00 40 00 00 02 8A 78
					39 00 00 40 00 00 04 FF 5A A5 20 // sync setting
					15 00 00 40 00 00 02 BB 05
					39 00 00 40 00 00 04 FF 5A A5 00
					39 00 00 40 00 00 04 FF 5A A5 08 //ALL Done open CDM FIFO Reset
					15 00 00 40 00 00 02 98 A6
					39 00 00 40 00 00 04 FF 5A A5 00 //Dummy write
					15 00 00 40 00 00 02 00 00
					39 00 00 40 00 00 04 FF 5A A5 4F // PAGE 4F
					15 00 00 00 00 00 02 8B 78 // cmd core 0 queue all done
					39 00 00 00 00 00 04 FF 5A A5 00
					/* wait for te and blocking one frame */
					39 00 00 20 00 00 04 FF 5A A5 00
				];
				qcom,mdss-dsi-on-command = [
					39 00 00 40 00 00 04 FF 5A A5 08 // 1~2: Sleepoutdon'treload
					15 00 00 40 00 00 02 C8 62
					39 00 00 40 00 00 04 FF 5A A5 21 // 3~4:  Flashreloadenable
					15 00 00 40 00 00 02 A4 38
					39 00 00 40 00 00 04 FF 5A A5 23
					15 00 00 40 00 00 02 85 15
					39 00 00 40 00 00 04 FF 5A A5 06
					15 00 00 40 00 00 02 C6 01
					39 00 00 40 00 00 04 FF 5A A5 08
					15 00 00 40 00 00 02 D2 05
					15 00 00 40 00 00 02 D3 01
					39 00 00 40 00 00 09 ED FC 0C 06 00 E3 F1 09 FF
					39 00 00 00 00 00 09 EE FF FD 82 00 20 03 00 00

					39 00 00 40 00 00 04 FF 5A A5 22
					39 00 00 40 00 00 08 D8 01 03 11 10 3B 18 18 //120&60HZ
					39 00 00 40 00 00 08 D9 01 01 11 10 3B 18 18 //90HZ
					39 00 00 40 00 00 08 DA 00 F8 11 10 2E 17 17 //144HZ
					39 00 00 40 00 00 08 DB 00 F9 11 10 2E 17 17 //165HZ
					39 00 00 40 00 00 0A DC 84 94 BB 00 20 C4 A1 CC 10
					15 00 00 40 00 00 02 DD 01
					15 00 00 40 00 00 02 DE F1
					15 00 00 40 00 00 02 DF 80
					39 00 00 40 00 00 07 E0 02 00 5F 21 00 28

					39 00 00 40 00 00 04 FF 5A A5 02 // sync setting
					39 00 00 40 00 00 03 B0 00 83
					39 00 00 40 00 00 04 FF 5A A5 2D
					15 00 00 40 00 00 02 F6 12
					39 00 00 40 00 00 18 EF 00 00 00 00 00 00 00 00 00 00 00 00 00 00 00 00 00 00 00 00 00 40 0B
					39 00 00 40 00 00 18 F0 00 00 00 00 00 00 00 00 00 00 00 00 00 00 00 00 00 00 00 00 00 40 0B
					39 00 00 40 00 00 04 FF 5A A5 1C // Implementation of measures for addressing abnormal power-on issues of VCI, dvt has already opt
					39 00 00 40 00 00 3A E3 08 00 00 77 01 00 04 14 00 04 14 00 38 10 00 38 10 00 D4 00 00 28 24 00 44 30 00 D4 30 00 47 30 00 F0 00 00 89 00 00 89 00 00 44 00 00 08 00 00 7B 00 00 7B 00 00 24 00 00
					39 00 00 40 00 00 04 FF 5A A5 20 // Correct the reverse configuration of sync settings; dvt has already opt
					15 00 00 40 00 00 02 BA 04 //VSYNC
					15 00 00 00 00 00 02 BB 05 //HSYNC

					39 00 00 40 00 00 04 FF 5A A5 00
					15 00 00 40 00 00 02 7D 00
					15 00 00 40 00 00 02 5E 01
					15 00 00 40 00 00 02 60 00
					15 00 00 40 00 00 02 61 03
					15 00 00 40 00 00 02 6D 01
					15 00 00 40 00 00 02 35 00 // TE on
					15 00 00 40 00 00 02 53 20 // BCOn
					// 165hz
					39 00 00 40 00 00 04 FF 5A A5 00
					15 00 00 00 00 00 02 60 02
					// Evt Output enable for Hsync and Vsync
					39 00 00 40 00 00 04 FF 5A A5 20
					15 00 00 40 00 00 02 BA 04
					15 00 00 00 00 00 02 BB 05
					// ODC ON
					39 00 00 40 00 00 04 FF 5A A5 49
					15 00 00 40 00 00 02 E0 01
					// add demura para
					39 00 00 40 00 00 04 FF 5A A5 53
					15 00 00 40 00 00 02 F0 01
					39 00 00 40 00 00 04 FF 5A A5 63
					39 00 00 40 00 00 11 F1 20 20 20 20 20 20 20 20 20 20 00 00 00 00 00 00
					39 00 00 40 00 00 11 F2 80 80 80 80 80 80 80 80 80 80 00 00 00 00 00 00
					39 00 00 40 00 00 11 F3 00 00 00 00 00 00 00 00 00 00 00 00 00 00 00 00
					39 00 00 40 00 00 11 F4 00 00 00 00 00 00 00 00 00 00 00 00 00 00 00 00
					39 00 00 40 00 00 04 FF 5A A5 53
					15 00 00 00 00 00 02 F0 00

					15 00 00 00 78 00 02 11 00
					15 00 00 00 14 00 02 29 00
				];
				qcom,mdss-dsi-off-command=[
					05 00 00 00 14 00 01 28
					05 00 00 00 78 00 01 10
				];
				qcom,mdss-dsi-hbm-off-command = [
				];
				qcom,mdss-dsi-hbm-on-command = [
				];
				qcom,mdss-dsi-change-voltage-before-bl-0-command = [
				];
				qcom,mdss-dsi-lhbm-pressed-icon-on-command = [
				];
				qcom,mdss-dsi-lhbm-pressed-icon-off-command = [
				];
				qcom,mdss-dsi-lp1-command = [
					39 00 00 40 00 00 04 FF 5A A5 08
					15 00 00 40 00 00 02 98 02
					39 00 00 40 00 00 04 FF 5A A5 4F
					15 00 00 40 00 00 02 80 01
					15 00 00 40 00 00 02 81 06
					15 00 00 40 00 00 02 88 78
					39 00 00 40 00 00 04 FF 5A A5 02
					39 00 00 40 00 00 03 84 01 1E
					39 00 00 40 00 00 04 FF 5A A5 00
					15 00 00 40 00 00 02 39 00
					39 00 00 40 00 00 04 FF 5A A5 08
					15 00 00 40 00 00 02 98 A6
					39 00 00 40 00 00 04 FF 5A A5 00
					15 00 00 40 00 00 02 00 00
					39 00 00 40 00 00 04 FF 5A A5 4F
					15 00 00 00 00 00 02 8B 78
					39 00 00 00 00 00 05 51 00 00 03 DA
				];
				qcom,mdss-dsi-nolp-command = [
					39 00 00 40 00 00 04 FF 5A A5 08
					15 00 00 40 00 00 02 98 02
					39 00 00 40 00 00 04 FF 5A A5 4F
					15 00 00 40 00 00 02 80 01
					15 00 00 40 00 00 02 81 06
					15 00 00 40 00 00 02 88 78
					39 00 00 40 00 00 04 FF 5A A5 02
					39 00 00 40 00 00 03 84 01 05
					39 00 00 40 00 00 04 FF 5A A5 00
					15 00 00 40 00 00 02 38 00
					39 00 00 40 00 00 04 FF 5A A5 08
					15 00 00 40 00 00 02 98 A6
					39 00 00 40 00 00 04 FF 5A A5 00
					15 00 00 40 00 00 02 00 00
					39 00 00 40 00 00 04 FF 5A A5 4F
					15 00 00 00 00 00 02 8B 78
				];
				qcom,mdss-dsi-aod-off-pwm-mode2-command = [
				];
				qcom,mdss-dsi-aod-off-compensation-command = [
				];
				qcom,mdss-dsi-aod-off-compensation-onepulse-command = [
				];
				qcom,mdss-dsi-aod-high-mode-command = [
					39 00 00 40 00 00 04 FF 5A A5 00
					39 00 00 00 00 00 05 51 00 00 03 DA
				];
				qcom,mdss-dsi-aod-low-mode-command = [
					39 00 00 40 00 00 04 FF 5A A5 00
					39 00 00 00 00 00 05 51 00 00 01 B9
				];
				qcom,mdss-dsi-ultra-low-power-aod-on-command = [
				];
				qcom,mdss-dsi-ultra-low-power-aod-off-command = [
				];
				/* pwm */
				qcom,mdss-dsi-pwm-state-l3tol2-command = [
				];
				qcom,mdss-dsi-pwm-state-l2tol3-command = [
				];
				qcom,mdss-dsi-pwm-switch-mode0-command= [
				];
				qcom,mdss-dsi-pwm-switch-mode2-command = [
				];
				qcom,mdss-dsi-timming-switch-pwm-mode2-command = [
				];
				qcom,mdss-dsi-pwm-switch-mode2-panel-on-command = [
				];
				qcom,mdss-dsi-pwm-state-l1tol3-command = [
				];
				qcom,mdss-dsi-pwm-state-l3tol1-command = [
				];
				qcom,mdss-dsi-hbm-max-command = [
				];
				qcom,mdss-dsi-hbm-exit-max-command = [
				];
				qcom,mdss-dsi-lp1-command-state = "dsi_lp_sync1_mode";
				qcom,mdss-dsi-nolp-command-state = "dsi_lp_sync1_mode";
				qcom,mdss-dsi-aod-off-pwm-mode2-command-state = "dsi_hs_sync1_mode";
				qcom,mdss-dsi-aod-off-compensation-command-state = "dsi_lp_sync1_mode";
				qcom,mdss-dsi-aod-off-compensation-onepulse-command-state = "dsi_lp_sync1_mode";
				qcom,mdss-dsi-nolp-hpwm-command-state = "dsi_lp_sync1_mode";
				qcom,mdss-dsi-hbm-on-command-state = "dsi_hs_sync1_mode";
				qcom,mdss-dsi-hbm-off-command-state = "dsi_hs_sync1_mode";
				qcom,mdss-dsi-panel-read-register-open-state = "dsi_lp_mode";
				qcom,mdss-dsi-panel-read-register-close-state = "dsi_lp_mode";
				qcom,mdss-dsi-lhbm-pressed-icon-gamma-command-state = "dsi_lp_mode";
				qcom,mdss-dsi-lhbm-pressed-icon-grayscale-command-state = "dsi_lp_mode";
				qcom,mdss-dsi-lhbm-pressed-icon-on-command-state = "dsi_lp_mode";
				qcom,mdss-dsi-lhbm-pressed-icon-off-command-state = "dsi_lp_mode";
				qcom,mdss-dsi-lhbm-dbv-alpha-command-state = "dsi_hs_mode";

				qcom,mdss-dsi-reset-scanline-command-state = "dsi_hs_mode";
				qcom,mdss-dsi-recovery-scanline-command-state = "dsi_hs_mode";

				qcom,mdss-dsi-osc-track-on-command-state = "dsi_hs_mode";
				qcom,mdss-dsi-osc-track-off-command-state = "dsi_hs_mode";
				qcom,mdss-dsi-hbm-max-command-state = "dsi_hs_mode";
				qcom,mdss-dsi-hbm-exit-max-command-state = "dsi_hs_mode";

				qcom,lm-split = <636 636>;
				qcom,compression-mode = "dsc";
				qcom,mdss-dsc-encoders = <2>;
				qcom,mdss-dsc-slice-height = <20>;
				qcom,mdss-dsc-slice-width = <636>;
				qcom,mdss-dsc-slice-per-pkt = <2>;
				qcom,mdss-dsc-bit-per-component = <10>;
				qcom,mdss-dsc-bit-per-pixel = <8>;
				qcom,mdss-dsc-block-prediction-enable;
			};
		};
	};
};

&soc {
	dsi_panel_AA605_P_7_A0020_dsc_cmd {
		qcom,dsi-display-active;
	};
};

&dsi_panel_AA605_P_7_A0020_dsc_cmd {
	qcom,panel-supply-entries = <&oplus_dsi_panel_custom_pwr_supply>;
	qcom,platform-te-gpio = <&tlmm 86 0>;
	qcom,platform-reset-gpio = <&tlmm 98 0>;
	oplus,panel-gpio1 = <&pm8550ve_g_gpios 4 0>;
	oplus,panel-gpio2 = <&pm8550ve_f_gpios 7 0>;

	oplus,panel-reset-position = <0x02>;
	oplus,panel-power-on-sequence = "1", "gpio1", "1", "vddio", "3", "gpio2", "3", "vci", "10";
	oplus,panel-power-off-sequence = "1", "vci", "3", "gpio2", "3", "vddio", "1", "gpio1", "1";

	//enable mipi strength
	oplus,enhance_mipi_strength;

	/* BRIGHTNESS CONFIG */
	qcom,mdss-dsi-bl-pmic-control-type = "bl_ctrl_dcs";
	qcom,bl-update-flag = "delay_until_first_frame";
	qcom,mdss-dsi-bl-inverted-dbv;
	qcom,mdss-dsi-bl-min-level = <1>;
	qcom,mdss-dsi-bl-max-level = <4094>;
	qcom,mdss-brightness-max-level = <4094>;
	oplus,dsi-bl-normal-max-level = <3515>;
	oplus,dsi-brightness-normal-max-level = <3515>;
	oplus,dsi-dc-backlight-threshold = <1960>;
	oplus,dsi-brightness-default-level = <1638>;

	/* ESD CONFIG */
	qcom,esd-check-enabled;
	oplus,esd-check-flag-enabled;
	qcom,mdss-dsi-panel-status-check-mode = "reg_read";
	qcom,mdss-dsi-panel-status-command = [
			06 00 00 00 00 00 01 0A
		];
	qcom,mdss-dsi-panel-status-command-state = "dsi_lp_mode";
	qcom,mdss-dsi-panel-status-value = <
			0x9C
	>;
	qcom,mdss-dsi-panel-status-read-length = <1>;
	oplus,mdss-dsi-panel-status-match-modes = <0x00000000>;

	/* FACTORY CONFIG */
	oplus,mdss-dsi-vendor-name = "A0020";
	oplus,mdss-dsi-manufacture = "P_7";
	oplus,color_vivid_status;
	oplus,color_srgb_status;
	oplus,color_softiris_status;
	oplus,color_dual_brightness_status;
	oplus,color_2nit_status;
	oplus,color_oplus_calibrate_status;
	oplus,color_samsung_status;
	oplus,color_loading_status;
	oplus,color_nature_profession_status;
	oplus,mdss-dsi-panel-type = <2>;

	/* OPLUS FEATURES CONFIG */
	oplus,dsi-serial-number-enabled;
	oplus,dsi-serial-number-switch-page;
	oplus,dsi-serial-number-index= <0>;
	oplus,dsi-serial-number-reg= <0x80>;
	oplus,dsi-serial-number-read-count= <7>;
	oplus,dsi-serial-number-base-year = <2020>;
	qcom,ulps-enabled;
	qcom,dsi-select-clocks = "pll_byte_clk0", "pll_dsi_clk0";

	oplus,vreg_ctrl_flag;

	/* ofp config */
	oplus,ofp-fp-type = <0xC0>;
	oplus,ofp-longrui-aod-config = <0x06>;
	oplus,ofp-need-to-wait-data-before-aod-on;
	oplus,ofp-aod-off-frame-cost = <1>;
	/* adfr config */
	// oplus,adfr-config = <0xe51>;  // 0b0000'0000'0101'0001
	// oplus,adfr-test-te-gpio = <&tlmm 85 0>;
	/* just for qsync enable*/
	qcom,qsync-enable;
	qcom,mdss-dsi-qsync-min-refresh-rate = <30>;

	/* panel dynamic te support config 61hz 122hz Epic:8906208 */
	oplus,dynamic-float-te-support = <1>;

	// qcom,dsi-dyn-clk-enable;
	qcom,mdss-dsi-display-timings {
		timing@sdc_fhd_120 { /* FHD+ 120hz 1107 Mbps */
			qcom,mdss-dsi-panel-phy-timings = [00 24 0A 0A 1A 18 0A 0A 09 02 04 00 1E 0F];
			qcom,display-topology = <1 1 1>,<2 2 1>;
			qcom,default-topology-index = <1>;
			qcom,dsi-mode-te-width-us = <315>;
		};
		timing@sdc_fhd_90 { /* FHD+ 90hz  1107 Mbps */
			qcom,mdss-dsi-panel-phy-timings = [00 24 0A 0A 1A 18 0A 0A 09 02 04 00 1E 0F];
			qcom,display-topology = <1 1 1>,<2 2 1>;
			qcom,default-topology-index = <1>;
			qcom,dsi-mode-te-width-us = <315>;
		};
		timing@sdc_fhd_60 { /* FHD+ 60hz 1107 Mbps */
			qcom,mdss-dsi-panel-phy-timings = [00 24 0A 0A 1A 18 0A 0A 09 02 04 00 1E 0F];
			qcom,display-topology = <1 1 1>,<2 2 1>;
			qcom,default-topology-index = <1>;
			qcom,dsi-mode-te-width-us = <315>;
		};
		timing@sdc_fhd_144 { /* FHD+ 144hz 1363 Mbps */
			qcom,mdss-dsi-panel-phy-timings = [00 2C 0C 0C 1D 1A 0C 0C 0B 02 04 00 24 11];
			qcom,display-topology = <1 1 1>,<2 2 1>;
			qcom,default-topology-index = <1>;
			qcom,dsi-mode-te-width-us = <315>;
		};
		timing@sdc_fhd_165 { /* FHD+ 120hz 1363 Mbps */
			qcom,mdss-dsi-panel-phy-timings = [00 2C 0C 0C 1D 1A 0C 0C 0B 02 04 00 24 11];
			qcom,display-topology = <1 1 1>,<2 2 1>;
			qcom,default-topology-index = <1>;
			qcom,dsi-mode-te-width-us = <315>;
		};
	};
};

&dsi_panel_AA605_P_7_A0020_dsc_cmd {
	qcom,mdss-dsi-display-timings {
		timing@sdc_fhd_120 { /* FHD+ 120hz 1094.4Mbps */
			/* standard adfr */
			qcom,disable-rsc-solver;
			qcom,mdss-dsi-h-sync-skew = <0>;
			oplus,adfr-min-fps-mapping-table = <120 60 30 20 10 1>;
			oplus,adfr-idle-off-min-fps = <20>;
			oplus,adfr-high-precision-fps-mapping-table = <120 90 72 60>;
		};
	};
};

&dsi_panel_AA605_P_7_A0020_dsc_cmd {
	qcom,panel_voltage_vddi_name = "vddio";
	qcom,panel_voltage_vddi = <0 1800000 1850000 1950000>;
	qcom,panel_voltage_vddr_name = "vddio";
	qcom,panel_voltage_vddr = <1 1800000 1850000 1950000>;
};

&dsi_panel_AA605_P_7_A0020_dsc_cmd{
	/* demura dbv config */

	/* pwm config */
	/*	oplus,pwm-switch-config:
		Bit0: pwm feature enable
		Bit1: pwm mode switch enable, need to config switch cmds
		Bit2: force enabled pwm mode switch cmd, will send mode cmd even dbv threshold cmd feature is configed
		Bit3: pwm dbv threshold pulse switch enable, need to config threshold switch cmds
		Bit4: wait te before sending pwm dbv threshold pulse switch cmd
		Bit5: replace specific cmd to other cmd while in pwm 1pulse mode
		Bit6: sending extend cmd while panel power on accroding to current pwm mode
		Bit7: sending extend cmd while timing switch accroding to current pwm pulse level
		Bit8: sending extend cmd after sending dbv threshold cmd in another thread
		...
		Bit24:support pwm mode0
		Bit25:support pwm mode1
		Bit26:support pwm mode2
	*/
	oplus,pwm-switch-config = <0x06000067>;
	/*	oplus,pwm-switch-mode0-states-info/oplus,pwm-switch-mode1-states-info:
		Specific dbv threshold and pulse info of 2 pwm mode, for pulse, 0 symbols 1pulse,
		1symbols 3pulse and 2 symbols 18pulse. The format should be 1 dbv threshold info with
		2 pwm pulse levels left and right(for example, <2 1087 1> means 18pulse while dbv <= 1087
		and 3pulse while dbv > 1087), or only one pulse level, no threshold.
	*/
	// oplus,pwm-switch-mode0-states-info = <2 1162 1>;
	// oplus,pwm-switch-mode1-states-info = <2 1162 0>;
	// oplus,pwm-switch-mode2-states-info = <0>;
	/*	oplus,pwm-mode1-cmd-switch-map/oplus,pwm-mode2-cmd-switch-map;
		Specific cmd replace relationship while in switch on(1pulse) mode. It is a string array that
		compose with cmd names, every 2 names combine 1 map. For example, map "'a', 'b'" means replace
		a to b while sending a in switch on mode.
	*/
	oplus,pwm-mode2-cmd-switch-map = "qcom,mdss-dsi-nolp-command", "qcom,mdss-dsi-aod-off-pwm-mode2-command",
			"qcom,mdss-dsi-timing-switch-command", "qcom,mdss-dsi-timming-switch-pwm-mode2-command";

	oplus,pwm-compatible-mode;
	oplus,cmdq-sync-support;
	oplus,change-voltage-before-panel-bl-0-enable;
	oplus,interval-time-nolp-pre;

	// oplus,gamma-compensation-support;
};
